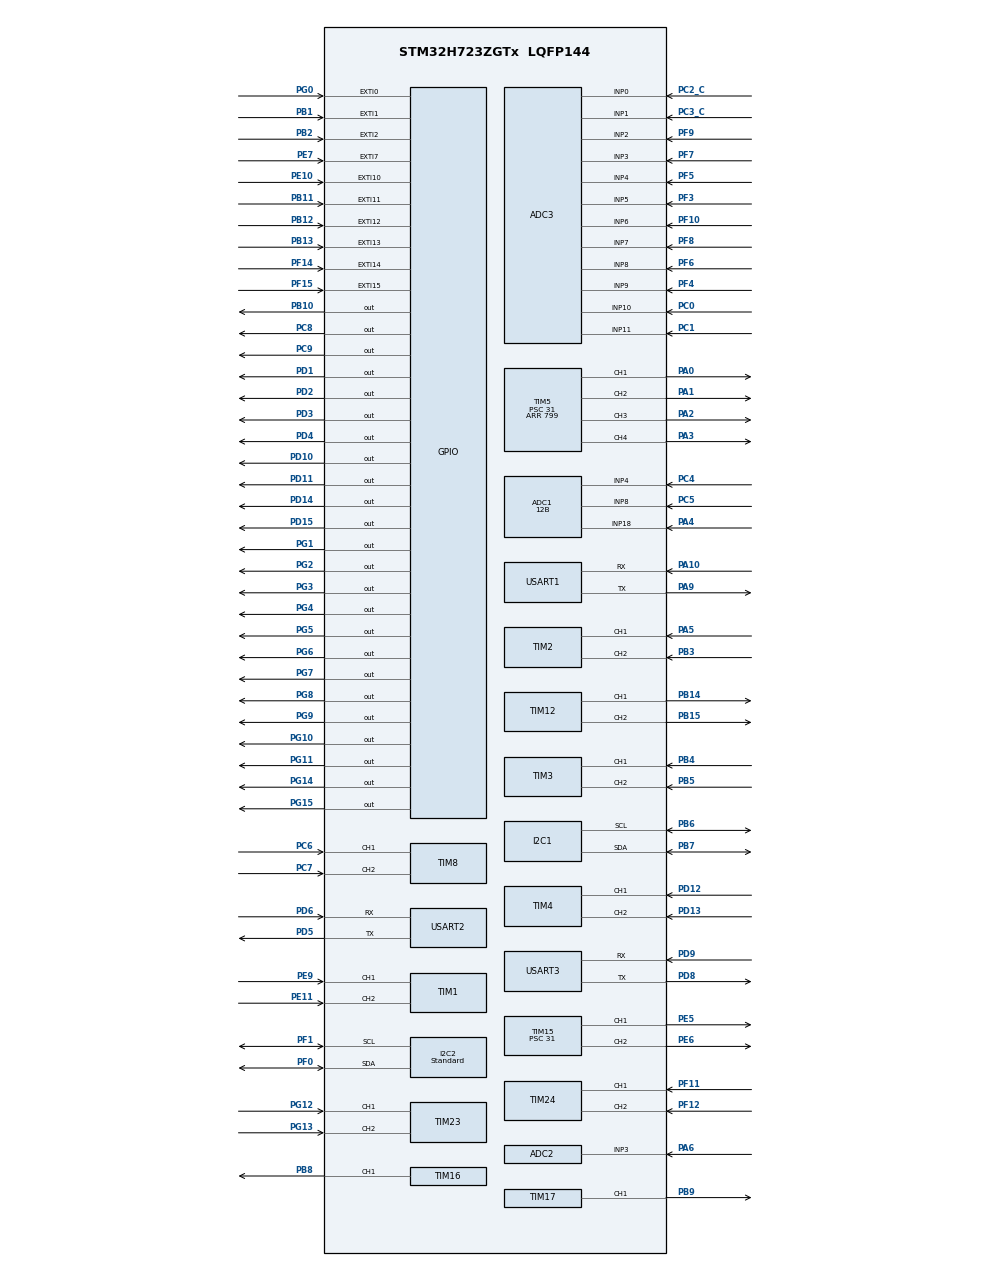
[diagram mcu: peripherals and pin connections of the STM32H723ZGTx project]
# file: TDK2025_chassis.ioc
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ADC1.Channel-0\#ChannelRegularConversion=ADC_CHANNEL_4
ADC1.Channel-1\#ChannelRegularConversion=ADC_CHANNEL_8
ADC1.Channel-2\#ChannelRegularConversion=ADC_CHANNEL_18
ADC1.ClockPrescaler=ADC_CLOCK_ASYNC_DIV256
ADC1.ClockPrescalerADC3=ADC_CLOCK_ASYNC_DIV64
ADC1.ContinuousConvMode=ENABLE
ADC1.ConversionDataManagement=ADC_CONVERSIONDATA_DR
ADC1.EOCSelection=ADC_EOC_SINGLE_CONV
ADC1.EnableInjectedConversion=DISABLE
ADC1.ExternalTrigConv=ADC_SOFTWARE_START
ADC1.NbrOfConversion=3
ADC1.NbrOfConversionFlag=1
ADC1.OffsetNumber-0\#ChannelRegularConversion=ADC_OFFSET_NONE
ADC1.OffsetNumber-1\#ChannelRegularConversion=ADC_OFFSET_NONE
ADC1.OffsetNumber-2\#ChannelRegularConversion=ADC_OFFSET_NONE
ADC1.OffsetSignedSaturation-0\#ChannelRegularConversion=DISABLE
ADC1.OffsetSignedSaturation-1\#ChannelRegularConversion=DISABLE
ADC1.OffsetSignedSaturation-2\#ChannelRegularConversion=DISABLE
ADC1.OversamplingMode=ENABLE
ADC1.Rank-0\#ChannelRegularConversion=1
ADC1.Rank-1\#ChannelRegularConversion=2
ADC1.Rank-2\#ChannelRegularConversion=3
ADC1.Ratio=2
ADC1.Resolution=ADC_RESOLUTION_12B
ADC1.SamplingTime-0\#ChannelRegularConversion=ADC_SAMPLETIME_2CYCLES_5
ADC1.SamplingTime-1\#ChannelRegularConversion=ADC_SAMPLETIME_2CYCLES_5
ADC1.SamplingTime-2\#ChannelRegularConversion=ADC_SAMPLETIME_2CYCLES_5
ADC1.master=1
ADC2.Channel-2\#ChannelRegularConversion=ADC_CHANNEL_3
ADC2.ClockPrescaler=ADC_CLOCK_ASYNC_DIV256
ADC2.ClockPrescalerADC3=ADC_CLOCK_ASYNC_DIV64
ADC2.NbrOfConversionFlag=1
ADC2.OffsetNumber-2\#ChannelRegularConversion=ADC_OFFSET_NONE
ADC2.OffsetSignedSaturation-2\#ChannelRegularConversion=DISABLE
ADC2.OversamplingMode=ENABLE
ADC2.Rank-2\#ChannelRegularConversion=1
ADC2.SamplingTime-2\#ChannelRegularConversion=ADC_SAMPLETIME_1CYCLE_5
ADC3.Channel-0\#ChannelRegularConversion=ADC_CHANNEL_0
ADC3.Channel-1\#ChannelRegularConversion=ADC_CHANNEL_1
ADC3.Channel-10\#ChannelRegularConversion=ADC_CHANNEL_10
ADC3.Channel-11\#ChannelRegularConversion=ADC_CHANNEL_11
ADC3.Channel-2\#ChannelRegularConversion=ADC_CHANNEL_2
ADC3.Channel-3\#ChannelRegularConversion=ADC_CHANNEL_3
ADC3.Channel-4\#ChannelRegularConversion=ADC_CHANNEL_4
ADC3.Channel-5\#ChannelRegularConversion=ADC_CHANNEL_5
ADC3.Channel-6\#ChannelRegularConversion=ADC_CHANNEL_6
ADC3.Channel-7\#ChannelRegularConversion=ADC_CHANNEL_7
ADC3.Channel-8\#ChannelRegularConversion=ADC_CHANNEL_8
ADC3.Channel-9\#ChannelRegularConversion=ADC_CHANNEL_9
ADC3.ClockPrescaler=ADC_CLOCK_ASYNC_DIV256
ADC3.ClockPrescalerADC3=ADC_CLOCK_ASYNC_DIV64
ADC3.ContinuousConvMode=ENABLE
ADC3.ConversionDataManagement=ADC_CONVERSIONDATA_DMA_CIRCULAR
ADC3.DMAContinuousRequests=ENABLE
ADC3.ExternalTrigConv=ADC_SOFTWARE_START
ADC3.NbrOfConversion=12
ADC3.NbrOfConversionFlag=1
ADC3.OffsetNumber-0\#ChannelRegularConversion=ADC_OFFSET_NONE
ADC3.OffsetNumber-1\#ChannelRegularConversion=ADC_OFFSET_NONE
ADC3.OffsetNumber-10\#ChannelRegularConversion=ADC_OFFSET_NONE
ADC3.OffsetNumber-11\#ChannelRegularConversion=ADC_OFFSET_NONE
ADC3.OffsetNumber-2\#ChannelRegularConversion=ADC_OFFSET_NONE
ADC3.OffsetNumber-3\#ChannelRegularConversion=ADC_OFFSET_NONE
ADC3.OffsetNumber-4\#ChannelRegularConversion=ADC_OFFSET_NONE
ADC3.OffsetNumber-5\#ChannelRegularConversion=ADC_OFFSET_NONE
ADC3.OffsetNumber-6\#ChannelRegularConversion=ADC_OFFSET_NONE
ADC3.OffsetNumber-7\#ChannelRegularConversion=ADC_OFFSET_NONE
ADC3.OffsetNumber-8\#ChannelRegularConversion=ADC_OFFSET_NONE
ADC3.OffsetNumber-9\#ChannelRegularConversion=ADC_OFFSET_NONE
ADC3.OffsetSign-0\#ChannelRegularConversion=ADC3_OFFSET_SIGN_NEGATIVE
ADC3.OffsetSign-1\#ChannelRegularConversion=ADC3_OFFSET_SIGN_NEGATIVE
ADC3.OffsetSign-10\#ChannelRegularConversion=ADC3_OFFSET_SIGN_NEGATIVE
ADC3.OffsetSign-11\#ChannelRegularConversion=ADC3_OFFSET_SIGN_NEGATIVE
ADC3.OffsetSign-2\#ChannelRegularConversion=ADC3_OFFSET_SIGN_NEGATIVE
ADC3.OffsetSign-3\#ChannelRegularConversion=ADC3_OFFSET_SIGN_NEGATIVE
ADC3.OffsetSign-4\#ChannelRegularConversion=ADC3_OFFSET_SIGN_NEGATIVE
ADC3.OffsetSign-5\#ChannelRegularConversion=ADC3_OFFSET_SIGN_NEGATIVE
ADC3.OffsetSign-6\#ChannelRegularConversion=ADC3_OFFSET_SIGN_NEGATIVE
ADC3.OffsetSign-7\#ChannelRegularConversion=ADC3_OFFSET_SIGN_NEGATIVE
ADC3.OffsetSign-8\#ChannelRegularConversion=ADC3_OFFSET_SIGN_NEGATIVE
ADC3.OffsetSign-9\#ChannelRegularConversion=ADC3_OFFSET_SIGN_NEGATIVE
ADC3.Rank-0\#ChannelRegularConversion=1
ADC3.Rank-1\#ChannelRegularConversion=2
ADC3.Rank-10\#ChannelRegularConversion=11
ADC3.Rank-11\#ChannelRegularConversion=12
ADC3.Rank-2\#ChannelRegularConversion=3
ADC3.Rank-3\#ChannelRegularConversion=4
ADC3.Rank-4\#ChannelRegularConversion=5
ADC3.Rank-5\#ChannelRegularConversion=6
ADC3.Rank-6\#ChannelRegularConversion=7
ADC3.Rank-7\#ChannelRegularConversion=8
ADC3.Rank-8\#ChannelRegularConversion=9
ADC3.Rank-9\#ChannelRegularConversion=10
ADC3.SamplingTime-0\#ChannelRegularConversion=ADC3_SAMPLETIME_2CYCLES_5
ADC3.SamplingTime-1\#ChannelRegularConversion=ADC3_SAMPLETIME_2CYCLES_5
ADC3.SamplingTime-10\#ChannelRegularConversion=ADC3_SAMPLETIME_2CYCLES_5
ADC3.SamplingTime-11\#ChannelRegularConversion=ADC3_SAMPLETIME_2CYCLES_5
ADC3.SamplingTime-2\#ChannelRegularConversion=ADC3_SAMPLETIME_2CYCLES_5
ADC3.SamplingTime-3\#ChannelRegularConversion=ADC3_SAMPLETIME_2CYCLES_5
ADC3.SamplingTime-4\#ChannelRegularConversion=ADC3_SAMPLETIME_2CYCLES_5
ADC3.SamplingTime-5\#ChannelRegularConversion=ADC3_SAMPLETIME_2CYCLES_5
ADC3.SamplingTime-6\#ChannelRegularConversion=ADC3_SAMPLETIME_2CYCLES_5
ADC3.SamplingTime-7\#ChannelRegularConversion=ADC3_SAMPLETIME_2CYCLES_5
ADC3.SamplingTime-8\#ChannelRegularConversion=ADC3_SAMPLETIME_2CYCLES_5
ADC3.SamplingTime-9\#ChannelRegularConversion=ADC3_SAMPLETIME_2CYCLES_5
Dma.ADC1.3.Direction=DMA_PERIPH_TO_MEMORY
Dma.ADC1.3.EventEnable=DISABLE
Dma.ADC1.3.FIFOMode=DMA_FIFOMODE_DISABLE
Dma.ADC1.3.Instance=DMA1_Stream0
Dma.ADC1.3.MemDataAlignment=DMA_MDATAALIGN_HALFWORD
Dma.ADC1.3.MemInc=DMA_MINC_ENABLE
Dma.ADC1.3.Mode=DMA_CIRCULAR
Dma.ADC1.3.PeriphDataAlignment=DMA_PDATAALIGN_HALFWORD
Dma.ADC1.3.PeriphInc=DMA_PINC_DISABLE
Dma.ADC1.3.Polarity=HAL_DMAMUX_REQ_GEN_RISING
Dma.ADC1.3.Priority=DMA_PRIORITY_LOW
Dma.ADC1.3.RequestNumber=1
Dma.ADC1.3.SignalID=NONE
Dma.ADC1.3.SyncEnable=DISABLE
Dma.ADC1.3.SyncPolarity=HAL_DMAMUX_SYNC_NO_EVENT
Dma.ADC1.3.SyncRequestNumber=1
Dma.ADC1.3.SyncSignalID=NONE
Dma.ADC3.2.Direction=DMA_PERIPH_TO_MEMORY
Dma.ADC3.2.EventEnable=DISABLE
Dma.ADC3.2.FIFOMode=DMA_FIFOMODE_DISABLE
Dma.ADC3.2.Instance=DMA1_Stream5
Dma.ADC3.2.MemDataAlignment=DMA_MDATAALIGN_HALFWORD
Dma.ADC3.2.MemInc=DMA_MINC_ENABLE
Dma.ADC3.2.Mode=DMA_CIRCULAR
Dma.ADC3.2.PeriphDataAlignment=DMA_PDATAALIGN_HALFWORD
Dma.ADC3.2.PeriphInc=DMA_PINC_DISABLE
Dma.ADC3.2.Polarity=HAL_DMAMUX_REQ_GEN_RISING
Dma.ADC3.2.Priority=DMA_PRIORITY_LOW
Dma.ADC3.2.RequestNumber=1
Dma.ADC3.2.SignalID=NONE
Dma.ADC3.2.SyncEnable=DISABLE
Dma.ADC3.2.SyncPolarity=HAL_DMAMUX_SYNC_NO_EVENT
Dma.ADC3.2.SyncRequestNumber=1
Dma.ADC3.2.SyncSignalID=NONE
Dma.I2C1_RX.4.Direction=DMA_PERIPH_TO_MEMORY
Dma.I2C1_RX.4.EventEnable=DISABLE
Dma.I2C1_RX.4.FIFOMode=DMA_FIFOMODE_DISABLE
Dma.I2C1_RX.4.Instance=DMA1_Stream6
Dma.I2C1_RX.4.MemDataAlignment=DMA_MDATAALIGN_BYTE
Dma.I2C1_RX.4.MemInc=DMA_MINC_ENABLE
Dma.I2C1_RX.4.Mode=DMA_NORMAL
Dma.I2C1_RX.4.PeriphDataAlignment=DMA_PDATAALIGN_BYTE
Dma.I2C1_RX.4.PeriphInc=DMA_PINC_DISABLE
Dma.I2C1_RX.4.Polarity=HAL_DMAMUX_REQ_GEN_RISING
Dma.I2C1_RX.4.Priority=DMA_PRIORITY_LOW
Dma.I2C1_RX.4.RequestNumber=1
Dma.I2C1_RX.4.SignalID=NONE
Dma.I2C1_RX.4.SyncEnable=DISABLE
Dma.I2C1_RX.4.SyncPolarity=HAL_DMAMUX_SYNC_NO_EVENT
Dma.I2C1_RX.4.SyncRequestNumber=1
Dma.I2C1_RX.4.SyncSignalID=NONE
Dma.I2C2_RX.5.Direction=DMA_PERIPH_TO_MEMORY
Dma.I2C2_RX.5.EventEnable=DISABLE
Dma.I2C2_RX.5.FIFOMode=DMA_FIFOMODE_DISABLE
Dma.I2C2_RX.5.Instance=DMA1_Stream2
Dma.I2C2_RX.5.MemDataAlignment=DMA_MDATAALIGN_BYTE
Dma.I2C2_RX.5.MemInc=DMA_MINC_ENABLE
Dma.I2C2_RX.5.Mode=DMA_NORMAL
Dma.I2C2_RX.5.PeriphDataAlignment=DMA_PDATAALIGN_BYTE
Dma.I2C2_RX.5.PeriphInc=DMA_PINC_DISABLE
Dma.I2C2_RX.5.Polarity=HAL_DMAMUX_REQ_GEN_RISING
Dma.I2C2_RX.5.Priority=DMA_PRIORITY_HIGH
Dma.I2C2_RX.5.RequestNumber=1
Dma.I2C2_RX.5.SignalID=NONE
Dma.I2C2_RX.5.SyncEnable=DISABLE
Dma.I2C2_RX.5.SyncPolarity=HAL_DMAMUX_SYNC_NO_EVENT
Dma.I2C2_RX.5.SyncRequestNumber=1
Dma.I2C2_RX.5.SyncSignalID=NONE
Dma.I2C2_TX.6.Direction=DMA_MEMORY_TO_PERIPH
Dma.I2C2_TX.6.EventEnable=DISABLE
Dma.I2C2_TX.6.FIFOMode=DMA_FIFOMODE_DISABLE
Dma.I2C2_TX.6.Instance=DMA1_Stream3
Dma.I2C2_TX.6.MemDataAlignment=DMA_MDATAALIGN_BYTE
Dma.I2C2_TX.6.MemInc=DMA_MINC_ENABLE
Dma.I2C2_TX.6.Mode=DMA_NORMAL
Dma.I2C2_TX.6.PeriphDataAlignment=DMA_PDATAALIGN_BYTE
Dma.I2C2_TX.6.PeriphInc=DMA_PINC_DISABLE
Dma.I2C2_TX.6.Polarity=HAL_DMAMUX_REQ_GEN_RISING
Dma.I2C2_TX.6.Priority=DMA_PRIORITY_MEDIUM
Dma.I2C2_TX.6.RequestNumber=1
Dma.I2C2_TX.6.SignalID=NONE
Dma.I2C2_TX.6.SyncEnable=DISABLE
Dma.I2C2_TX.6.SyncPolarity=HAL_DMAMUX_SYNC_NO_EVENT
Dma.I2C2_TX.6.SyncRequestNumber=1
Dma.I2C2_TX.6.SyncSignalID=NONE
Dma.Request0=USART1_TX
Dma.Request1=USART1_RX
Dma.Request2=ADC3
Dma.Request3=ADC1
Dma.Request4=I2C1_RX
Dma.Request5=I2C2_RX
Dma.Request6=I2C2_TX
Dma.Request7=USART3_RX
Dma.Request8=USART3_TX
Dma.USART1_RX.1.Direction=DMA_PERIPH_TO_MEMORY
Dma.USART1_RX.1.EventEnable=DISABLE
Dma.USART1_RX.1.FIFOMode=DMA_FIFOMODE_DISABLE
Dma.USART1_RX.1.Instance=DMA1_Stream1
Dma.USART1_RX.1.MemDataAlignment=DMA_MDATAALIGN_BYTE
Dma.USART1_RX.1.MemInc=DMA_MINC_ENABLE
Dma.USART1_RX.1.Mode=DMA_CIRCULAR
Dma.USART1_RX.1.PeriphDataAlignment=DMA_PDATAALIGN_BYTE
Dma.USART1_RX.1.PeriphInc=DMA_PINC_DISABLE
Dma.USART1_RX.1.Polarity=HAL_DMAMUX_REQ_GEN_RISING
Dma.USART1_RX.1.Priority=DMA_PRIORITY_VERY_HIGH
Dma.USART1_RX.1.RequestNumber=1
Dma.USART1_RX.1.SignalID=NONE
Dma.USART1_RX.1.SyncEnable=DISABLE
Dma.USART1_RX.1.SyncPolarity=HAL_DMAMUX_SYNC_NO_EVENT
Dma.USART1_RX.1.SyncRequestNumber=1
Dma.USART1_RX.1.SyncSignalID=NONE
Dma.USART1_TX.0.Direction=DMA_MEMORY_TO_PERIPH
Dma.USART1_TX.0.EventEnable=DISABLE
Dma.USART1_TX.0.FIFOMode=DMA_FIFOMODE_DISABLE
Dma.USART1_TX.0.Instance=DMA1_Stream4
Dma.USART1_TX.0.MemDataAlignment=DMA_MDATAALIGN_BYTE
Dma.USART1_TX.0.MemInc=DMA_MINC_ENABLE
Dma.USART1_TX.0.Mode=DMA_NORMAL
Dma.USART1_TX.0.PeriphDataAlignment=DMA_PDATAALIGN_BYTE
Dma.USART1_TX.0.PeriphInc=DMA_PINC_DISABLE
Dma.USART1_TX.0.Polarity=HAL_DMAMUX_REQ_GEN_RISING
Dma.USART1_TX.0.Priority=DMA_PRIORITY_VERY_HIGH
Dma.USART1_TX.0.RequestNumber=1
Dma.USART1_TX.0.SignalID=NONE
Dma.USART1_TX.0.SyncEnable=DISABLE
Dma.USART1_TX.0.SyncPolarity=HAL_DMAMUX_SYNC_NO_EVENT
Dma.USART1_TX.0.SyncRequestNumber=1
Dma.USART1_TX.0.SyncSignalID=NONE
Dma.USART3_RX.7.Direction=DMA_PERIPH_TO_MEMORY
Dma.USART3_RX.7.EventEnable=DISABLE
Dma.USART3_RX.7.FIFOMode=DMA_FIFOMODE_DISABLE
Dma.USART3_RX.7.Instance=DMA1_Stream7
Dma.USART3_RX.7.MemDataAlignment=DMA_MDATAALIGN_BYTE
Dma.USART3_RX.7.MemInc=DMA_MINC_ENABLE
Dma.USART3_RX.7.Mode=DMA_CIRCULAR
Dma.USART3_RX.7.PeriphDataAlignment=DMA_PDATAALIGN_BYTE
Dma.USART3_RX.7.PeriphInc=DMA_PINC_DISABLE
Dma.USART3_RX.7.Polarity=HAL_DMAMUX_REQ_GEN_RISING
Dma.USART3_RX.7.Priority=DMA_PRIORITY_VERY_HIGH
Dma.USART3_RX.7.RequestNumber=1
Dma.USART3_RX.7.SignalID=NONE
Dma.USART3_RX.7.SyncEnable=DISABLE
Dma.USART3_RX.7.SyncPolarity=HAL_DMAMUX_SYNC_NO_EVENT
Dma.USART3_RX.7.SyncRequestNumber=1
Dma.USART3_RX.7.SyncSignalID=NONE
Dma.USART3_TX.8.Direction=DMA_MEMORY_TO_PERIPH
Dma.USART3_TX.8.EventEnable=DISABLE
Dma.USART3_TX.8.FIFOMode=DMA_FIFOMODE_DISABLE
Dma.USART3_TX.8.Instance=DMA2_Stream0
Dma.USART3_TX.8.MemDataAlignment=DMA_MDATAALIGN_BYTE
Dma.USART3_TX.8.MemInc=DMA_MINC_ENABLE
Dma.USART3_TX.8.Mode=DMA_NORMAL
Dma.USART3_TX.8.PeriphDataAlignment=DMA_PDATAALIGN_BYTE
Dma.USART3_TX.8.PeriphInc=DMA_PINC_DISABLE
Dma.USART3_TX.8.Polarity=HAL_DMAMUX_REQ_GEN_RISING
Dma.USART3_TX.8.Priority=DMA_PRIORITY_VERY_HIGH
Dma.USART3_TX.8.RequestNumber=1
Dma.USART3_TX.8.SignalID=NONE
Dma.USART3_TX.8.SyncEnable=DISABLE
Dma.USART3_TX.8.SyncPolarity=HAL_DMAMUX_SYNC_NO_EVENT
Dma.USART3_TX.8.SyncRequestNumber=1
Dma.USART3_TX.8.SyncSignalID=NONE
I2C1.Timing=0x20A0C4DF
I2C2.I2C_Fall_Time=0
I2C2.I2C_Rise_Time=0
I2C2.I2C_Speed_Mode=I2C_Standard
I2C2.Timing=0x20A0C4DF
Mcu.Family=STM32H7
Mcu.Name=STM32H723ZGTx
Mcu.Package=LQFP144
NVIC.ADC3_IRQn=true\:1\:0\:true\:false\:true\:true\:true\:true
NVIC.ADC_IRQn=true\:0\:0\:false\:false\:true\:true\:true\:true
NVIC.DMA1_Stream0_IRQn=true\:0\:0\:true\:false\:true\:false\:true\:true
NVIC.DMA1_Stream1_IRQn=true\:0\:0\:false\:false\:true\:false\:true\:true
NVIC.DMA1_Stream2_IRQn=true\:0\:0\:false\:false\:true\:false\:true\:true
NVIC.DMA1_Stream3_IRQn=true\:0\:0\:false\:false\:true\:false\:true\:true
NVIC.DMA1_Stream4_IRQn=true\:0\:0\:false\:false\:true\:false\:true\:true
NVIC.DMA1_Stream5_IRQn=true\:0\:0\:false\:false\:true\:false\:true\:true
NVIC.DMA1_Stream6_IRQn=true\:0\:0\:false\:false\:true\:false\:true\:true
NVIC.DMA1_Stream7_IRQn=true\:0\:0\:false\:false\:true\:false\:true\:true
NVIC.DMA2_Stream0_IRQn=true\:0\:0\:false\:false\:true\:false\:true\:true
NVIC.EXTI0_IRQn=true\:0\:0\:false\:false\:true\:true\:true\:true
NVIC.EXTI15_10_IRQn=true\:0\:0\:false\:false\:true\:true\:true\:true
NVIC.EXTI1_IRQn=true\:0\:0\:false\:false\:true\:true\:true\:true
NVIC.EXTI2_IRQn=true\:0\:0\:false\:false\:true\:true\:true\:true
NVIC.EXTI9_5_IRQn=true\:0\:0\:false\:false\:true\:true\:true\:true
NVIC.I2C2_ER_IRQn=true\:0\:0\:false\:false\:true\:true\:true\:true
NVIC.I2C2_EV_IRQn=true\:0\:0\:false\:false\:true\:true\:true\:true
NVIC.PriorityGroup=NVIC_PRIORITYGROUP_4
NVIC.RCC_IRQn=true\:0\:0\:false\:false\:true\:true\:false\:true
NVIC.TIM6_DAC_IRQn=true\:0\:0\:false\:false\:true\:true\:true\:true
NVIC.TIM7_IRQn=true\:0\:0\:false\:false\:true\:true\:true\:true
NVIC.TIM8_TRG_COM_TIM14_IRQn=true\:0\:0\:false\:false\:true\:true\:true\:true
NVIC.TIM8_UP_TIM13_IRQn=true\:0\:0\:false\:false\:true\:true\:true\:true
NVIC.USART1_IRQn=true\:0\:0\:false\:false\:true\:true\:true\:true
NVIC.USART3_IRQn=true\:0\:0\:false\:false\:true\:true\:true\:true
PA0.GPIO_PuPd=GPIO_PULLDOWN
PA0.Signal=S_TIM5_CH1
PA1.GPIO_PuPd=GPIO_PULLDOWN
PA1.Signal=S_TIM5_CH2
PA10.Mode=Asynchronous
PA10.Signal=USART1_RX
PA13(JTMS/SWDIO).Signal=DEBUG_JTMS-SWDIO
PA14(JTCK/SWCLK).Signal=DEBUG_JTCK-SWCLK
PA2.GPIO_PuPd=GPIO_PULLDOWN
PA2.Signal=S_TIM5_CH3
PA3.GPIO_PuPd=GPIO_PULLDOWN
PA3.Signal=S_TIM5_CH4
PA4.Signal=ADCx_INP18
PA5.Signal=S_TIM2_CH1_ETR
PA6.Signal=ADCx_INP3
PA9.Mode=Asynchronous
PA9.Signal=USART1_TX
PB1.Signal=GPXTI1
PB10.PinState=GPIO_PIN_RESET
PB10.Signal=GPIO_Output
PB11.Signal=GPXTI11
PB12.Signal=GPXTI12
PB13.Signal=GPXTI13
PB14.Signal=S_TIM12_CH1
PB15.Signal=S_TIM12_CH2
PB2.GPIO_ModeDefaultEXTI=GPIO_MODE_IT_FALLING
PB2.GPIO_PuPd=GPIO_PULLUP
PB2.Signal=GPXTI2
PB3(JTDO/TRACESWO).Signal=S_TIM2_CH2
PB4(NJTRST).Signal=S_TIM3_CH1
PB5.Signal=S_TIM3_CH2
PB6.GPIO_Pu=GPIO_PULLUP
PB6.Mode=I2C
PB6.Signal=I2C1_SCL
PB7.GPIO_Pu=GPIO_PULLUP
PB7.Mode=I2C
PB7.Signal=I2C1_SDA
PB8.Signal=S_TIM16_CH1
PB9.Signal=S_TIM17_CH1
PC0.Signal=ADCx_INP10
PC1.Signal=ADCx_INP11
PC14-OSC32_IN.Mode=LSE-External-Oscillator
PC14-OSC32_IN.Signal=RCC_OSC32_IN
PC15-OSC32_OUT.Mode=LSE-External-Oscillator
PC15-OSC32_OUT.Signal=RCC_OSC32_OUT
PC2_C.Mode=IN0-Single-Ended
PC2_C.Signal=ADC3_INP0
PC3_C.Mode=IN1-Single-Ended
PC3_C.Signal=ADC3_INP1
PC4.Signal=ADCx_INP4
PC5.Signal=ADCx_INP8
PC6.Signal=S_TIM8_CH1
PC7.Signal=S_TIM8_CH2
PC8.Signal=GPIO_Output
PC9.Signal=GPIO_Output
PD1.Signal=GPIO_Output
PD10.Signal=GPIO_Output
PD11.Signal=GPIO_Output
PD12.Signal=S_TIM4_CH1
PD13.Signal=S_TIM4_CH2
PD14.Signal=GPIO_Output
PD15.Signal=GPIO_Output
PD2.Signal=GPIO_Output
PD3.Signal=GPIO_Output
PD4.Signal=GPIO_Output
PD5.Mode=Asynchronous
PD5.Signal=USART2_TX
PD6.Mode=Asynchronous
PD6.Signal=USART2_RX
PD8.Mode=Asynchronous
PD8.Signal=USART3_TX
PD9.Mode=Asynchronous
PD9.Signal=USART3_RX
PE10.Signal=GPXTI10
PE11.Signal=S_TIM1_CH2
PE5.Signal=S_TIM15_CH1
PE6.Signal=S_TIM15_CH2
PE7.Signal=GPXTI7
PE9.Signal=S_TIM1_CH1
PF0.GPIO_Pu=GPIO_PULLUP
PF0.Mode=I2C
PF0.Signal=I2C2_SDA
PF1.GPIO_Pu=GPIO_PULLUP
PF1.Mode=I2C
PF1.Signal=I2C2_SCL
PF10.Mode=IN6-Single-Ended
PF10.Signal=ADC3_INP6
PF11.Mode=Encoder_Interface
PF11.Signal=TIM24_CH1
PF12.Signal=S_TIM24_CH2
PF14.Signal=GPXTI14
PF15.Signal=GPXTI15
PF3.Mode=IN5-Single-Ended
PF3.Signal=ADC3_INP5
PF4.Mode=IN9-Single-Ended
PF4.Signal=ADC3_INP9
PF5.Mode=IN4-Single-Ended
PF5.Signal=ADC3_INP4
PF6.Mode=IN8-Single-Ended
PF6.Signal=ADC3_INP8
PF7.Mode=IN3-Single-Ended
PF7.Signal=ADC3_INP3
PF8.Mode=IN7-Single-Ended
PF8.Signal=ADC3_INP7
PF9.Mode=IN2-Single-Ended
PF9.Signal=ADC3_INP2
PG0.Signal=GPXTI0
PG1.Signal=GPIO_Output
PG10.Signal=GPIO_Output
PG11.Signal=GPIO_Output
PG12.Mode=Encoder_Interface
PG12.Signal=TIM23_CH1
PG13.Signal=S_TIM23_CH2
PG14.Signal=GPIO_Output
PG15.Signal=GPIO_Output
PG2.Signal=GPIO_Output
PG3.Signal=GPIO_Output
PG4.Signal=GPIO_Output
PG5.Signal=GPIO_Output
PG6.Signal=GPIO_Output
PG7.Signal=GPIO_Output
PG8.Signal=GPIO_Output
PG9.Signal=GPIO_Output
PH0-OSC_IN.Mode=HSE-External-Oscillator
PH0-OSC_IN.Signal=RCC_OSC_IN
PH1-OSC_OUT.Mode=HSE-External-Oscillator
PH1-OSC_OUT.Signal=RCC_OSC_OUT
ProjectManager.HeapSize=0x200
ProjectManager.StackSize=0x400
ProjectManager.TargetToolchain=STM32CubeIDE
RCC.ADCFreq_Value=129000000
RCC.APB1Freq_Value=128000000
RCC.APB2Freq_Value=128000000
RCC.APB3Freq_Value=128000000
RCC.APB4Freq_Value=128000000
RCC.CortexFreq_Value=512000000
RCC.D1PPRE=RCC_APB3_DIV2
RCC.D2PPRE1=RCC_APB1_DIV2
RCC.D2PPRE2=RCC_APB2_DIV2
RCC.D3PPRE=RCC_APB4_DIV2
RCC.DIVM1=4
RCC.DIVN1=32
RCC.DIVP1=1
RCC.HCLKFreq_Value=256000000
RCC.HPRE=RCC_HCLK_DIV2
RCC.HSE_VALUE=8000000
RCC.PLL2FRACN=0
RCC.PLL3FRACN=0
RCC.PLLFRACN=0
RCC.SYSCLKFreq_VALUE=512000000
RCC.SYSCLKSource=RCC_SYSCLKSOURCE_PLLCLK
RCC.USBFreq_Value=256000000
SH.ADCx_INP10.0=ADC3_INP10,IN10-Single-Ended
SH.ADCx_INP11.0=ADC3_INP11,IN11-Single-Ended
SH.ADCx_INP18.0=ADC1_INP18,IN18-Single-Ended
SH.ADCx_INP3.0=ADC2_INP3,IN3-Single-Ended
SH.ADCx_INP4.0=ADC1_INP4,IN4-Single-Ended
SH.ADCx_INP8.0=ADC1_INP8,IN8-Single-Ended
SH.S_TIM12_CH1.0=TIM12_CH1,PWM Generation1 CH1
SH.S_TIM12_CH2.0=TIM12_CH2,PWM Generation2 CH2
SH.S_TIM15_CH1.0=TIM15_CH1,PWM Generation1 CH1
SH.S_TIM15_CH2.0=TIM15_CH2,PWM Generation2 CH2
SH.S_TIM16_CH1.0=TIM16_CH1,PWM Generation1 CH1
SH.S_TIM17_CH1.0=TIM17_CH1,PWM Generation1 CH1
SH.S_TIM1_CH1.0=TIM1_CH1,Encoder_Interface
SH.S_TIM1_CH2.0=TIM1_CH2,Encoder_Interface
SH.S_TIM23_CH2.0=TIM23_CH2,Encoder_Interface
SH.S_TIM24_CH2.0=TIM24_CH2,Encoder_Interface
SH.S_TIM2_CH1_ETR.0=TIM2_CH1,Encoder_Interface
SH.S_TIM2_CH2.0=TIM2_CH2,Encoder_Interface
SH.S_TIM3_CH1.0=TIM3_CH1,Encoder_Interface
SH.S_TIM3_CH2.0=TIM3_CH2,Encoder_Interface
SH.S_TIM4_CH1.0=TIM4_CH1,Encoder_Interface
SH.S_TIM4_CH2.0=TIM4_CH2,Encoder_Interface
SH.S_TIM5_CH1.0=TIM5_CH1,PWM Generation1 CH1
SH.S_TIM5_CH2.0=TIM5_CH2,PWM Generation2 CH2
SH.S_TIM5_CH3.0=TIM5_CH3,PWM Generation3 CH3
SH.S_TIM5_CH4.0=TIM5_CH4,PWM Generation4 CH4
SH.S_TIM8_CH1.0=TIM8_CH1,Encoder_Interface
SH.S_TIM8_CH2.0=TIM8_CH2,Encoder_Interface
TIM1.EncoderMode=TIM_ENCODERMODE_TI12
TIM12.Channel-PWM\ Generation1\ CH1=TIM_CHANNEL_1
TIM12.Channel-PWM\ Generation2\ CH2=TIM_CHANNEL_2
TIM13.Period=9999
TIM13.Prescaler=255
TIM14.Period=999
TIM14.Prescaler=255
TIM15.Channel-PWM\ Generation1\ CH1=TIM_CHANNEL_1
TIM15.Channel-PWM\ Generation2\ CH2=TIM_CHANNEL_2
TIM15.Period=799
TIM15.Prescaler=31
TIM16.Channel=TIM_CHANNEL_1
TIM16.Period=799
TIM16.Prescaler=31
TIM17.Channel=TIM_CHANNEL_1
TIM17.Period=799
TIM17.Prescaler=31
TIM2.EncoderMode=TIM_ENCODERMODE_TI12
TIM23.EncoderMode=TIM_ENCODERMODE_TI12
TIM24.EncoderMode=TIM_ENCODERMODE_TI12
TIM3.EncoderMode=TIM_ENCODERMODE_TI12
TIM4.EncoderMode=TIM_ENCODERMODE_TI12
TIM5.Channel-PWM\ Generation1\ CH1=TIM_CHANNEL_1
TIM5.Channel-PWM\ Generation2\ CH2=TIM_CHANNEL_2
TIM5.Channel-PWM\ Generation3\ CH3=TIM_CHANNEL_3
TIM5.Channel-PWM\ Generation4\ CH4=TIM_CHANNEL_4
TIM5.Period=799
TIM5.Prescaler=31
TIM6.Period=999
TIM6.Prescaler=255
TIM7.Period=9999
TIM7.Prescaler=255
TIM8.EncoderMode=TIM_ENCODERMODE_TI12
USART1.VirtualMode-Asynchronous=VM_ASYNC
USART2.VirtualMode-Asynchronous=VM_ASYNC
USART3.VirtualMode-Asynchronous=VM_ASYNC
VP_MEMORYMAP_VS_MEMORYMAP.Mode=CurAppReg
VP_TIM13_VS_ClockSourceINT.Mode=Enable_Timer
VP_TIM14_VS_ClockSourceINT.Mode=Enable_Timer
VP_TIM16_VS_ClockSourceINT.Mode=Enable_Timer
VP_TIM17_VS_ClockSourceINT.Mode=Enable_Timer
VP_TIM6_VS_ClockSourceINT.Mode=Enable_Timer
VP_TIM7_VS_ClockSourceINT.Mode=Enable_Timer
board=custom

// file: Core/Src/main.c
/* USER CODE BEGIN Header */
/**
  ******************************************************************************
  * @file           : main.c
  * @brief          : Main program body
  ******************************************************************************
  * @attention
  *
  * Copyright (c) 2025 STMicroelectronics.
  * All rights reserved.
  *
  * This software is licensed under terms that can be found in the LICENSE file
  * in the root directory of this software component.
  * If no LICENSE file comes with this software, it is provided AS-IS.
  *
  ******************************************************************************
  */
/* USER CODE END Header */
#include "main.h"

/* USER CODE BEGIN Includes */
#include "mainpp.h"
/* USER CODE END Includes */

ADC_HandleTypeDef hadc1;
ADC_HandleTypeDef hadc2;
ADC_HandleTypeDef hadc3;
DMA_HandleTypeDef hdma_adc1;
DMA_HandleTypeDef hdma_adc3;

I2C_HandleTypeDef hi2c1;
I2C_HandleTypeDef hi2c2;
DMA_HandleTypeDef hdma_i2c1_rx;
DMA_HandleTypeDef hdma_i2c2_rx;
DMA_HandleTypeDef hdma_i2c2_tx;

TIM_HandleTypeDef htim1;
TIM_HandleTypeDef htim2;
TIM_HandleTypeDef htim3;
TIM_HandleTypeDef htim4;
TIM_HandleTypeDef htim5;
TIM_HandleTypeDef htim6;
TIM_HandleTypeDef htim7;
TIM_HandleTypeDef htim8;
TIM_HandleTypeDef htim12;
TIM_HandleTypeDef htim13;
TIM_HandleTypeDef htim14;
TIM_HandleTypeDef htim15;
TIM_HandleTypeDef htim16;
TIM_HandleTypeDef htim17;
TIM_HandleTypeDef htim23;
TIM_HandleTypeDef htim24;

UART_HandleTypeDef huart1;
UART_HandleTypeDef huart2;
UART_HandleTypeDef huart3;
DMA_HandleTypeDef hdma_usart1_tx;
DMA_HandleTypeDef hdma_usart1_rx;
DMA_HandleTypeDef hdma_usart3_rx;
DMA_HandleTypeDef hdma_usart3_tx;

void SystemClock_Config(void);
void PeriphCommonClock_Config(void);
static void MX_GPIO_Init(void);
static void MX_DMA_Init(void);
static void MX_USART1_UART_Init(void);
static void MX_TIM4_Init(void);
static void MX_TIM5_Init(void);
static void MX_TIM6_Init(void);
static void MX_TIM15_Init(void);
static void MX_TIM1_Init(void);
static void MX_TIM2_Init(void);
static void MX_I2C1_Init(void);
static void MX_ADC3_Init(void);
static void MX_TIM7_Init(void);
static void MX_I2C2_Init(void);
static void MX_TIM12_Init(void);
static void MX_TIM23_Init(void);
static void MX_TIM24_Init(void);
static void MX_TIM8_Init(void);
static void MX_TIM13_Init(void);
static void MX_ADC1_Init(void);
static void MX_TIM3_Init(void);
static void MX_TIM16_Init(void);
static void MX_TIM17_Init(void);
static void MX_ADC2_Init(void);
static void MX_USART2_UART_Init(void);
static void MX_TIM14_Init(void);
static void MX_USART3_UART_Init(void);

int main(void)
{

  /* MCU Configuration--------------------------------------------------------*/

  /* Reset of all peripherals, Initializes the Flash interface and the Systick. */

	HAL_Init();

  /* Configure the system clock */
  SystemClock_Config();

  /* Configure the peripherals common clocks */
  PeriphCommonClock_Config();

  /* Initialize all configured peripherals */
  MX_GPIO_Init();
  MX_DMA_Init();
  MX_USART1_UART_Init();
  MX_TIM4_Init();
  MX_TIM5_Init();
  MX_TIM6_Init();
  MX_TIM15_Init();
  MX_TIM1_Init();
  MX_TIM2_Init();
  MX_I2C1_Init();
  MX_ADC3_Init();
  MX_TIM7_Init();
  MX_I2C2_Init();
  MX_TIM12_Init();
  MX_TIM23_Init();
  MX_TIM24_Init();
  MX_TIM8_Init();
  MX_TIM13_Init();
  MX_ADC1_Init();
  MX_TIM3_Init();
  MX_TIM16_Init();
  MX_TIM17_Init();
  MX_ADC2_Init();
  MX_USART2_UART_Init();
  MX_TIM14_Init();
  MX_USART3_UART_Init();
  /* USER CODE BEGIN 2 */
  //hadc1.Init.DMAContinuousRequests = ENABLE;
  main_function();
  /* USER CODE END 2 */

  /* Infinite loop */
  while (1)
  {

    /* USER CODE BEGIN 3 */
    // Chassis::update() 現在在 TIM6 中斷中執行
    // 主循環可以處理其他任務或休眠
   // HAL_Delay(100);  // 減少主循環的 CPU 佔用
  }
  /* USER CODE END 3 */
}

void SystemClock_Config(void)
{
  RCC_OscInitTypeDef RCC_OscInitStruct = {0};
  RCC_ClkInitTypeDef RCC_ClkInitStruct = {0};

  /** Supply configuration update enable
  */
  HAL_PWREx_ConfigSupply(PWR_LDO_SUPPLY);

  /** Configure the main internal regulator output voltage
  */
  __HAL_PWR_VOLTAGESCALING_CONFIG(PWR_REGULATOR_VOLTAGE_SCALE0);

  while(!__HAL_PWR_GET_FLAG(PWR_FLAG_VOSRDY)) {}

  /** Initializes the RCC Oscillators according to the specified parameters
  * in the RCC_OscInitTypeDef structure.
  */
  RCC_OscInitStruct.OscillatorType = RCC_OSCILLATORTYPE_HSI;
  RCC_OscInitStruct.HSIState = RCC_HSI_DIV1;
  RCC_OscInitStruct.HSICalibrationValue = 64;
  RCC_OscInitStruct.PLL.PLLState = RCC_PLL_ON;
  RCC_OscInitStruct.PLL.PLLSource = RCC_PLLSOURCE_HSI;
  RCC_OscInitStruct.PLL.PLLM = 4;
  RCC_OscInitStruct.PLL.PLLN = 32;
  RCC_OscInitStruct.PLL.PLLP = 1;
  RCC_OscInitStruct.PLL.PLLQ = 2;
  RCC_OscInitStruct.PLL.PLLR = 2;
  RCC_OscInitStruct.PLL.PLLRGE = RCC_PLL1VCIRANGE_3;
  RCC_OscInitStruct.PLL.PLLVCOSEL = RCC_PLL1VCOWIDE;
  RCC_OscInitStruct.PLL.PLLFRACN = 0;
  if (HAL_RCC_OscConfig(&RCC_OscInitStruct) != HAL_OK)
  {
    Error_Handler();
  }

  /** Initializes the CPU, AHB and APB buses clocks
  */
  RCC_ClkInitStruct.ClockType = RCC_CLOCKTYPE_HCLK|RCC_CLOCKTYPE_SYSCLK
                              |RCC_CLOCKTYPE_PCLK1|RCC_CLOCKTYPE_PCLK2
                              |RCC_CLOCKTYPE_D3PCLK1|RCC_CLOCKTYPE_D1PCLK1;
  RCC_ClkInitStruct.SYSCLKSource = RCC_SYSCLKSOURCE_PLLCLK;
  RCC_ClkInitStruct.SYSCLKDivider = RCC_SYSCLK_DIV1;
  RCC_ClkInitStruct.AHBCLKDivider = RCC_HCLK_DIV2;
  RCC_ClkInitStruct.APB3CLKDivider = RCC_APB3_DIV2;
  RCC_ClkInitStruct.APB1CLKDivider = RCC_APB1_DIV2;
  RCC_ClkInitStruct.APB2CLKDivider = RCC_APB2_DIV2;
  RCC_ClkInitStruct.APB4CLKDivider = RCC_APB4_DIV2;

  if (HAL_RCC_ClockConfig(&RCC_ClkInitStruct, FLASH_LATENCY_3) != HAL_OK)
  {
    Error_Handler();
  }
}

void PeriphCommonClock_Config(void)
{
  RCC_PeriphCLKInitTypeDef PeriphClkInitStruct = {0};

  /** Initializes the peripherals clock
  */
  PeriphClkInitStruct.PeriphClockSelection = RCC_PERIPHCLK_ADC;
  PeriphClkInitStruct.PLL2.PLL2M = 32;
  PeriphClkInitStruct.PLL2.PLL2N = 129;
  PeriphClkInitStruct.PLL2.PLL2P = 2;
  PeriphClkInitStruct.PLL2.PLL2Q = 2;
  PeriphClkInitStruct.PLL2.PLL2R = 2;
  PeriphClkInitStruct.PLL2.PLL2RGE = RCC_PLL2VCIRANGE_1;
  PeriphClkInitStruct.PLL2.PLL2VCOSEL = RCC_PLL2VCOWIDE;
  PeriphClkInitStruct.PLL2.PLL2FRACN = 0;
  PeriphClkInitStruct.AdcClockSelection = RCC_ADCCLKSOURCE_PLL2;
  if (HAL_RCCEx_PeriphCLKConfig(&PeriphClkInitStruct) != HAL_OK)
  {
    Error_Handler();
  }
}

static void MX_ADC1_Init(void)
{

  ADC_MultiModeTypeDef multimode = {0};
  ADC_ChannelConfTypeDef sConfig = {0};

  /** Common config
  */
  hadc1.Instance = ADC1;
  hadc1.Init.ClockPrescaler = ADC_CLOCK_ASYNC_DIV256;
  hadc1.Init.Resolution = ADC_RESOLUTION_12B;
  hadc1.Init.ScanConvMode = ADC_SCAN_ENABLE;
  hadc1.Init.EOCSelection = ADC_EOC_SINGLE_CONV;
  hadc1.Init.LowPowerAutoWait = DISABLE;
  hadc1.Init.ContinuousConvMode = ENABLE;
  hadc1.Init.NbrOfConversion = 3;
  hadc1.Init.DiscontinuousConvMode = DISABLE;
  hadc1.Init.ExternalTrigConv = ADC_SOFTWARE_START;
  hadc1.Init.ExternalTrigConvEdge = ADC_EXTERNALTRIGCONVEDGE_NONE;
  hadc1.Init.ConversionDataManagement = ADC_CONVERSIONDATA_DR;
  hadc1.Init.Overrun = ADC_OVR_DATA_PRESERVED;
  hadc1.Init.LeftBitShift = ADC_LEFTBITSHIFT_NONE;
  hadc1.Init.OversamplingMode = ENABLE;
  hadc1.Init.Oversampling.Ratio = 2;
  hadc1.Init.Oversampling.RightBitShift = ADC_RIGHTBITSHIFT_NONE;
  hadc1.Init.Oversampling.TriggeredMode = ADC_TRIGGEREDMODE_SINGLE_TRIGGER;
  hadc1.Init.Oversampling.OversamplingStopReset = ADC_REGOVERSAMPLING_CONTINUED_MODE;
  if (HAL_ADC_Init(&hadc1) != HAL_OK)
  {
    Error_Handler();
  }

  /** Configure the ADC multi-mode
  */
  multimode.Mode = ADC_MODE_INDEPENDENT;
  if (HAL_ADCEx_MultiModeConfigChannel(&hadc1, &multimode) != HAL_OK)
  {
    Error_Handler();
  }

  /** Configure Regular Channel
  */
  sConfig.Channel = ADC_CHANNEL_4;
  sConfig.Rank = ADC_REGULAR_RANK_1;
  sConfig.SamplingTime = ADC_SAMPLETIME_2CYCLES_5;
  sConfig.SingleDiff = ADC_SINGLE_ENDED;
  sConfig.OffsetNumber = ADC_OFFSET_NONE;
  sConfig.Offset = 0;
  sConfig.OffsetSignedSaturation = DISABLE;
  if (HAL_ADC_ConfigChannel(&hadc1, &sConfig) != HAL_OK)
  {
    Error_Handler();
  }

  /** Configure Regular Channel
  */
  sConfig.Channel = ADC_CHANNEL_8;
  sConfig.Rank = ADC_REGULAR_RANK_2;
  if (HAL_ADC_ConfigChannel(&hadc1, &sConfig) != HAL_OK)
  {
    Error_Handler();
  }

  /** Configure Regular Channel
  */
  sConfig.Channel = ADC_CHANNEL_18;
  sConfig.Rank = ADC_REGULAR_RANK_3;
  if (HAL_ADC_ConfigChannel(&hadc1, &sConfig) != HAL_OK)
  {
    Error_Handler();
  }

}

static void MX_ADC2_Init(void)
{

  ADC_ChannelConfTypeDef sConfig = {0};

  /** Common config
  */
  hadc2.Instance = ADC2;
  hadc2.Init.ClockPrescaler = ADC_CLOCK_ASYNC_DIV256;
  hadc2.Init.Resolution = ADC_RESOLUTION_16B;
  hadc2.Init.ScanConvMode = ADC_SCAN_DISABLE;
  hadc2.Init.EOCSelection = ADC_EOC_SINGLE_CONV;
  hadc2.Init.LowPowerAutoWait = DISABLE;
  hadc2.Init.ContinuousConvMode = DISABLE;
  hadc2.Init.NbrOfConversion = 1;
  hadc2.Init.DiscontinuousConvMode = DISABLE;
  hadc2.Init.ExternalTrigConv = ADC_SOFTWARE_START;
  hadc2.Init.ExternalTrigConvEdge = ADC_EXTERNALTRIGCONVEDGE_NONE;
  hadc2.Init.ConversionDataManagement = ADC_CONVERSIONDATA_DR;
  hadc2.Init.Overrun = ADC_OVR_DATA_PRESERVED;
  hadc2.Init.LeftBitShift = ADC_LEFTBITSHIFT_NONE;
  hadc2.Init.OversamplingMode = ENABLE;
  hadc2.Init.Oversampling.Ratio = 1;
  hadc2.Init.Oversampling.RightBitShift = ADC_RIGHTBITSHIFT_NONE;
  hadc2.Init.Oversampling.TriggeredMode = ADC_TRIGGEREDMODE_SINGLE_TRIGGER;
  hadc2.Init.Oversampling.OversamplingStopReset = ADC_REGOVERSAMPLING_CONTINUED_MODE;
  if (HAL_ADC_Init(&hadc2) != HAL_OK)
  {
    Error_Handler();
  }

  /** Configure Regular Channel
  */
  sConfig.Channel = ADC_CHANNEL_3;
  sConfig.Rank = ADC_REGULAR_RANK_1;
  sConfig.SamplingTime = ADC_SAMPLETIME_1CYCLE_5;
  sConfig.SingleDiff = ADC_SINGLE_ENDED;
  sConfig.OffsetNumber = ADC_OFFSET_NONE;
  sConfig.Offset = 0;
  sConfig.OffsetSignedSaturation = DISABLE;
  if (HAL_ADC_ConfigChannel(&hadc2, &sConfig) != HAL_OK)
  {
    Error_Handler();
  }

}

static void MX_ADC3_Init(void)
{

  ADC_ChannelConfTypeDef sConfig = {0};

  /** Common config
  */
  hadc3.Instance = ADC3;
  hadc3.Init.ClockPrescaler = ADC_CLOCK_ASYNC_DIV64;
  hadc3.Init.Resolution = ADC_RESOLUTION_12B;
  hadc3.Init.DataAlign = ADC3_DATAALIGN_RIGHT;
  hadc3.Init.ScanConvMode = ADC_SCAN_ENABLE;
  hadc3.Init.EOCSelection = ADC_EOC_SINGLE_CONV;
  hadc3.Init.LowPowerAutoWait = DISABLE;
  hadc3.Init.ContinuousConvMode = ENABLE;
  hadc3.Init.NbrOfConversion = 12;
  hadc3.Init.DiscontinuousConvMode = DISABLE;
  hadc3.Init.ExternalTrigConv = ADC_SOFTWARE_START;
  hadc3.Init.ExternalTrigConvEdge = ADC_EXTERNALTRIGCONVEDGE_NONE;
  hadc3.Init.DMAContinuousRequests = ENABLE;
  hadc3.Init.SamplingMode = ADC_SAMPLING_MODE_NORMAL;
  hadc3.Init.ConversionDataManagement = ADC_CONVERSIONDATA_DMA_CIRCULAR;
  hadc3.Init.Overrun = ADC_OVR_DATA_PRESERVED;
  hadc3.Init.LeftBitShift = ADC_LEFTBITSHIFT_NONE;
  hadc3.Init.OversamplingMode = DISABLE;
  hadc3.Init.Oversampling.Ratio = ADC3_OVERSAMPLING_RATIO_2;
  if (HAL_ADC_Init(&hadc3) != HAL_OK)
  {
    Error_Handler();
  }

  /** Configure Regular Channel
  */
  sConfig.Channel = ADC_CHANNEL_0;
  sConfig.Rank = ADC_REGULAR_RANK_1;
  sConfig.SamplingTime = ADC3_SAMPLETIME_2CYCLES_5;
  sConfig.SingleDiff = ADC_SINGLE_ENDED;
  sConfig.OffsetNumber = ADC_OFFSET_NONE;
  sConfig.Offset = 0;
  sConfig.OffsetSign = ADC3_OFFSET_SIGN_NEGATIVE;
  if (HAL_ADC_ConfigChannel(&hadc3, &sConfig) != HAL_OK)
  {
    Error_Handler();
  }

  /** Configure Regular Channel
  */
  sConfig.Channel = ADC_CHANNEL_1;
  sConfig.Rank = ADC_REGULAR_RANK_2;
  if (HAL_ADC_ConfigChannel(&hadc3, &sConfig) != HAL_OK)
  {
    Error_Handler();
  }

  /** Configure Regular Channel
  */
  sConfig.Channel = ADC_CHANNEL_2;
  sConfig.Rank = ADC_REGULAR_RANK_3;
  if (HAL_ADC_ConfigChannel(&hadc3, &sConfig) != HAL_OK)
  {
    Error_Handler();
  }

  /** Configure Regular Channel
  */
  sConfig.Channel = ADC_CHANNEL_3;
  sConfig.Rank = ADC_REGULAR_RANK_4;
  if (HAL_ADC_ConfigChannel(&hadc3, &sConfig) != HAL_OK)
  {
    Error_Handler();
  }

  /** Configure Regular Channel
  */
  sConfig.Channel = ADC_CHANNEL_4;
  sConfig.Rank = ADC_REGULAR_RANK_5;
  if (HAL_ADC_ConfigChannel(&hadc3, &sConfig) != HAL_OK)
  {
    Error_Handler();
  }

  /** Configure Regular Channel
  */
  sConfig.Channel = ADC_CHANNEL_5;
  sConfig.Rank = ADC_REGULAR_RANK_6;
  if (HAL_ADC_ConfigChannel(&hadc3, &sConfig) != HAL_OK)
  {
    Error_Handler();
  }

  /** Configure Regular Channel
  */
  sConfig.Channel = ADC_CHANNEL_6;
  sConfig.Rank = ADC_REGULAR_RANK_7;
  if (HAL_ADC_ConfigChannel(&hadc3, &sConfig) != HAL_OK)
  {
    Error_Handler();
  }

  /** Configure Regular Channel
  */
  sConfig.Channel = ADC_CHANNEL_7;
  sConfig.Rank = ADC_REGULAR_RANK_8;
  if (HAL_ADC_ConfigChannel(&hadc3, &sConfig) != HAL_OK)
  {
    Error_Handler();
  }

  /** Configure Regular Channel
  */
  sConfig.Channel = ADC_CHANNEL_8;
  sConfig.Rank = ADC_REGULAR_RANK_9;
  if (HAL_ADC_ConfigChannel(&hadc3, &sConfig) != HAL_OK)
  {
    Error_Handler();
  }

  /** Configure Regular Channel
  */
  sConfig.Channel = ADC_CHANNEL_9;
  sConfig.Rank = ADC_REGULAR_RANK_10;
  if (HAL_ADC_ConfigChannel(&hadc3, &sConfig) != HAL_OK)
  {
    Error_Handler();
  }

  /** Configure Regular Channel
  */
  sConfig.Channel = ADC_CHANNEL_10;
  sConfig.Rank = ADC_REGULAR_RANK_11;
  if (HAL_ADC_ConfigChannel(&hadc3, &sConfig) != HAL_OK)
  {
    Error_Handler();
  }

  /** Configure Regular Channel
  */
  sConfig.Channel = ADC_CHANNEL_11;
  sConfig.Rank = ADC_REGULAR_RANK_12;
  if (HAL_ADC_ConfigChannel(&hadc3, &sConfig) != HAL_OK)
  {
    Error_Handler();
  }

}

static void MX_I2C1_Init(void)
{

  hi2c1.Instance = I2C1;
  hi2c1.Init.Timing = 0x20A0C4DF;
  hi2c1.Init.OwnAddress1 = 0;
  hi2c1.Init.AddressingMode = I2C_ADDRESSINGMODE_7BIT;
  hi2c1.Init.DualAddressMode = I2C_DUALADDRESS_DISABLE;
  hi2c1.Init.OwnAddress2 = 0;
  hi2c1.Init.OwnAddress2Masks = I2C_OA2_NOMASK;
  hi2c1.Init.GeneralCallMode = I2C_GENERALCALL_DISABLE;
  hi2c1.Init.NoStretchMode = I2C_NOSTRETCH_DISABLE;
  if (HAL_I2C_Init(&hi2c1) != HAL_OK)
  {
    Error_Handler();
  }

  /** Configure Analogue filter
  */
  if (HAL_I2CEx_ConfigAnalogFilter(&hi2c1, I2C_ANALOGFILTER_ENABLE) != HAL_OK)
  {
    Error_Handler();
  }

  /** Configure Digital filter
  */
  if (HAL_I2CEx_ConfigDigitalFilter(&hi2c1, 0) != HAL_OK)
  {
    Error_Handler();
  }

}

static void MX_I2C2_Init(void)
{

  hi2c2.Instance = I2C2;
  hi2c2.Init.Timing = 0x20A0C4DF;
  hi2c2.Init.OwnAddress1 = 0;
  hi2c2.Init.AddressingMode = I2C_ADDRESSINGMODE_7BIT;
  hi2c2.Init.DualAddressMode = I2C_DUALADDRESS_DISABLE;
  hi2c2.Init.OwnAddress2 = 0;
  hi2c2.Init.OwnAddress2Masks = I2C_OA2_NOMASK;
  hi2c2.Init.GeneralCallMode = I2C_GENERALCALL_DISABLE;
  hi2c2.Init.NoStretchMode = I2C_NOSTRETCH_DISABLE;
  if (HAL_I2C_Init(&hi2c2) != HAL_OK)
  {
    Error_Handler();
  }

  /** Configure Analogue filter
  */
  if (HAL_I2CEx_ConfigAnalogFilter(&hi2c2, I2C_ANALOGFILTER_ENABLE) != HAL_OK)
  {
    Error_Handler();
  }

  /** Configure Digital filter
  */
  if (HAL_I2CEx_ConfigDigitalFilter(&hi2c2, 0) != HAL_OK)
  {
    Error_Handler();
  }

}

static void MX_TIM1_Init(void)
{

  TIM_Encoder_InitTypeDef sConfig = {0};
  TIM_MasterConfigTypeDef sMasterConfig = {0};

  htim1.Instance = TIM1;
  htim1.Init.Prescaler = 0;
  htim1.Init.CounterMode = TIM_COUNTERMODE_UP;
  htim1.Init.Period = 65535;
  htim1.Init.ClockDivision = TIM_CLOCKDIVISION_DIV1;
  htim1.Init.RepetitionCounter = 0;
  htim1.Init.AutoReloadPreload = TIM_AUTORELOAD_PRELOAD_DISABLE;
  sConfig.EncoderMode = TIM_ENCODERMODE_TI12;
  sConfig.IC1Polarity = TIM_ICPOLARITY_RISING;
  sConfig.IC1Selection = TIM_ICSELECTION_DIRECTTI;
  sConfig.IC1Prescaler = TIM_ICPSC_DIV1;
  sConfig.IC1Filter = 0;
  sConfig.IC2Polarity = TIM_ICPOLARITY_RISING;
  sConfig.IC2Selection = TIM_ICSELECTION_DIRECTTI;
  sConfig.IC2Prescaler = TIM_ICPSC_DIV1;
  sConfig.IC2Filter = 0;
  if (HAL_TIM_Encoder_Init(&htim1, &sConfig) != HAL_OK)
  {
    Error_Handler();
  }
  sMasterConfig.MasterOutputTrigger = TIM_TRGO_RESET;
  sMasterConfig.MasterOutputTrigger2 = TIM_TRGO2_RESET;
  sMasterConfig.MasterSlaveMode = TIM_MASTERSLAVEMODE_DISABLE;
  if (HAL_TIMEx_MasterConfigSynchronization(&htim1, &sMasterConfig) != HAL_OK)
  {
    Error_Handler();
  }

}

static void MX_TIM2_Init(void)
{

  TIM_Encoder_InitTypeDef sConfig = {0};
  TIM_MasterConfigTypeDef sMasterConfig = {0};

  htim2.Instance = TIM2;
  htim2.Init.Prescaler = 0;
  htim2.Init.CounterMode = TIM_COUNTERMODE_UP;
  htim2.Init.Period = 4294967295;
  htim2.Init.ClockDivision = TIM_CLOCKDIVISION_DIV1;
  htim2.Init.AutoReloadPreload = TIM_AUTORELOAD_PRELOAD_DISABLE;
  sConfig.EncoderMode = TIM_ENCODERMODE_TI12;
  sConfig.IC1Polarity = TIM_ICPOLARITY_RISING;
  sConfig.IC1Selection = TIM_ICSELECTION_DIRECTTI;
  sConfig.IC1Prescaler = TIM_ICPSC_DIV1;
  sConfig.IC1Filter = 0;
  sConfig.IC2Polarity = TIM_ICPOLARITY_RISING;
  sConfig.IC2Selection = TIM_ICSELECTION_DIRECTTI;
  sConfig.IC2Prescaler = TIM_ICPSC_DIV1;
  sConfig.IC2Filter = 0;
  if (HAL_TIM_Encoder_Init(&htim2, &sConfig) != HAL_OK)
  {
    Error_Handler();
  }
  sMasterConfig.MasterOutputTrigger = TIM_TRGO_RESET;
  sMasterConfig.MasterSlaveMode = TIM_MASTERSLAVEMODE_DISABLE;
  if (HAL_TIMEx_MasterConfigSynchronization(&htim2, &sMasterConfig) != HAL_OK)
  {
    Error_Handler();
  }

}

static void MX_TIM3_Init(void)
{

  TIM_Encoder_InitTypeDef sConfig = {0};
  TIM_MasterConfigTypeDef sMasterConfig = {0};

  htim3.Instance = TIM3;
  htim3.Init.Prescaler = 0;
  htim3.Init.CounterMode = TIM_COUNTERMODE_UP;
  htim3.Init.Period = 65535;
  htim3.Init.ClockDivision = TIM_CLOCKDIVISION_DIV1;
  htim3.Init.AutoReloadPreload = TIM_AUTORELOAD_PRELOAD_DISABLE;
  sConfig.EncoderMode = TIM_ENCODERMODE_TI12;
  sConfig.IC1Polarity = TIM_ICPOLARITY_RISING;
  sConfig.IC1Selection = TIM_ICSELECTION_DIRECTTI;
  sConfig.IC1Prescaler = TIM_ICPSC_DIV1;
  sConfig.IC1Filter = 0;
  sConfig.IC2Polarity = TIM_ICPOLARITY_RISING;
  sConfig.IC2Selection = TIM_ICSELECTION_DIRECTTI;
  sConfig.IC2Prescaler = TIM_ICPSC_DIV1;
  sConfig.IC2Filter = 0;
  if (HAL_TIM_Encoder_Init(&htim3, &sConfig) != HAL_OK)
  {
    Error_Handler();
  }
  sMasterConfig.MasterOutputTrigger = TIM_TRGO_RESET;
  sMasterConfig.MasterSlaveMode = TIM_MASTERSLAVEMODE_DISABLE;
  if (HAL_TIMEx_MasterConfigSynchronization(&htim3, &sMasterConfig) != HAL_OK)
  {
    Error_Handler();
  }

}

static void MX_TIM4_Init(void)
{

  TIM_Encoder_InitTypeDef sConfig = {0};
  TIM_MasterConfigTypeDef sMasterConfig = {0};

  htim4.Instance = TIM4;
  htim4.Init.Prescaler = 0;
  htim4.Init.CounterMode = TIM_COUNTERMODE_UP;
  htim4.Init.Period = 65535;
  htim4.Init.ClockDivision = TIM_CLOCKDIVISION_DIV1;
  htim4.Init.AutoReloadPreload = TIM_AUTORELOAD_PRELOAD_DISABLE;
  sConfig.EncoderMode = TIM_ENCODERMODE_TI12;
  sConfig.IC1Polarity = TIM_ICPOLARITY_RISING;
  sConfig.IC1Selection = TIM_ICSELECTION_DIRECTTI;
  sConfig.IC1Prescaler = TIM_ICPSC_DIV1;
  sConfig.IC1Filter = 0;
  sConfig.IC2Polarity = TIM_ICPOLARITY_RISING;
  sConfig.IC2Selection = TIM_ICSELECTION_DIRECTTI;
  sConfig.IC2Prescaler = TIM_ICPSC_DIV1;
  sConfig.IC2Filter = 0;
  if (HAL_TIM_Encoder_Init(&htim4, &sConfig) != HAL_OK)
  {
    Error_Handler();
  }
  sMasterConfig.MasterOutputTrigger = TIM_TRGO_RESET;
  sMasterConfig.MasterSlaveMode = TIM_MASTERSLAVEMODE_DISABLE;
  if (HAL_TIMEx_MasterConfigSynchronization(&htim4, &sMasterConfig) != HAL_OK)
  {
    Error_Handler();
  }

}

static void MX_TIM5_Init(void)
{

  TIM_MasterConfigTypeDef sMasterConfig = {0};
  TIM_OC_InitTypeDef sConfigOC = {0};

  htim5.Instance = TIM5;
  htim5.Init.Prescaler = 31;
  htim5.Init.CounterMode = TIM_COUNTERMODE_UP;
  htim5.Init.Period = 799;
  htim5.Init.ClockDivision = TIM_CLOCKDIVISION_DIV1;
  htim5.Init.AutoReloadPreload = TIM_AUTORELOAD_PRELOAD_DISABLE;
  if (HAL_TIM_PWM_Init(&htim5) != HAL_OK)
  {
    Error_Handler();
  }
  sMasterConfig.MasterOutputTrigger = TIM_TRGO_RESET;
  sMasterConfig.MasterSlaveMode = TIM_MASTERSLAVEMODE_DISABLE;
  if (HAL_TIMEx_MasterConfigSynchronization(&htim5, &sMasterConfig) != HAL_OK)
  {
    Error_Handler();
  }
  sConfigOC.OCMode = TIM_OCMODE_PWM1;
  sConfigOC.Pulse = 0;
  sConfigOC.OCPolarity = TIM_OCPOLARITY_HIGH;
  sConfigOC.OCFastMode = TIM_OCFAST_DISABLE;
  if (HAL_TIM_PWM_ConfigChannel(&htim5, &sConfigOC, TIM_CHANNEL_1) != HAL_OK)
  {
    Error_Handler();
  }
  if (HAL_TIM_PWM_ConfigChannel(&htim5, &sConfigOC, TIM_CHANNEL_2) != HAL_OK)
  {
    Error_Handler();
  }
  if (HAL_TIM_PWM_ConfigChannel(&htim5, &sConfigOC, TIM_CHANNEL_3) != HAL_OK)
  {
    Error_Handler();
  }
  if (HAL_TIM_PWM_ConfigChannel(&htim5, &sConfigOC, TIM_CHANNEL_4) != HAL_OK)
  {
    Error_Handler();
  }
  HAL_TIM_MspPostInit(&htim5);

}

static void MX_TIM6_Init(void)
{

  TIM_MasterConfigTypeDef sMasterConfig = {0};

  htim6.Instance = TIM6;
  htim6.Init.Prescaler = 255;
  htim6.Init.CounterMode = TIM_COUNTERMODE_UP;
  htim6.Init.Period = 999;
  htim6.Init.AutoReloadPreload = TIM_AUTORELOAD_PRELOAD_DISABLE;
  if (HAL_TIM_Base_Init(&htim6) != HAL_OK)
  {
    Error_Handler();
  }
  sMasterConfig.MasterOutputTrigger = TIM_TRGO_RESET;
  sMasterConfig.MasterSlaveMode = TIM_MASTERSLAVEMODE_DISABLE;
  if (HAL_TIMEx_MasterConfigSynchronization(&htim6, &sMasterConfig) != HAL_OK)
  {
    Error_Handler();
  }

}

static void MX_TIM7_Init(void)
{

  TIM_MasterConfigTypeDef sMasterConfig = {0};

  htim7.Instance = TIM7;
  htim7.Init.Prescaler = 255;
  htim7.Init.CounterMode = TIM_COUNTERMODE_UP;
  htim7.Init.Period = 9999;
  htim7.Init.AutoReloadPreload = TIM_AUTORELOAD_PRELOAD_DISABLE;
  if (HAL_TIM_Base_Init(&htim7) != HAL_OK)
  {
    Error_Handler();
  }
  sMasterConfig.MasterOutputTrigger = TIM_TRGO_RESET;
  sMasterConfig.MasterSlaveMode = TIM_MASTERSLAVEMODE_DISABLE;
  if (HAL_TIMEx_MasterConfigSynchronization(&htim7, &sMasterConfig) != HAL_OK)
  {
    Error_Handler();
  }

}

static void MX_TIM8_Init(void)
{

  TIM_Encoder_InitTypeDef sConfig = {0};
  TIM_MasterConfigTypeDef sMasterConfig = {0};

  htim8.Instance = TIM8;
  htim8.Init.Prescaler = 0;
  htim8.Init.CounterMode = TIM_COUNTERMODE_UP;
  htim8.Init.Period = 65535;
  htim8.Init.ClockDivision = TIM_CLOCKDIVISION_DIV1;
  htim8.Init.RepetitionCounter = 0;
  htim8.Init.AutoReloadPreload = TIM_AUTORELOAD_PRELOAD_DISABLE;
  sConfig.EncoderMode = TIM_ENCODERMODE_TI12;
  sConfig.IC1Polarity = TIM_ICPOLARITY_RISING;
  sConfig.IC1Selection = TIM_ICSELECTION_DIRECTTI;
  sConfig.IC1Prescaler = TIM_ICPSC_DIV1;
  sConfig.IC1Filter = 0;
  sConfig.IC2Polarity = TIM_ICPOLARITY_RISING;
  sConfig.IC2Selection = TIM_ICSELECTION_DIRECTTI;
  sConfig.IC2Prescaler = TIM_ICPSC_DIV1;
  sConfig.IC2Filter = 0;
  if (HAL_TIM_Encoder_Init(&htim8, &sConfig) != HAL_OK)
  {
    Error_Handler();
  }
  sMasterConfig.MasterOutputTrigger = TIM_TRGO_RESET;
  sMasterConfig.MasterOutputTrigger2 = TIM_TRGO2_RESET;
  sMasterConfig.MasterSlaveMode = TIM_MASTERSLAVEMODE_DISABLE;
  if (HAL_TIMEx_MasterConfigSynchronization(&htim8, &sMasterConfig) != HAL_OK)
  {
    Error_Handler();
  }

}

static void MX_TIM12_Init(void)
{

  TIM_MasterConfigTypeDef sMasterConfig = {0};
  TIM_OC_InitTypeDef sConfigOC = {0};

  htim12.Instance = TIM12;
  htim12.Init.Prescaler = 0;
  htim12.Init.CounterMode = TIM_COUNTERMODE_UP;
  htim12.Init.Period = 65535;
  htim12.Init.ClockDivision = TIM_CLOCKDIVISION_DIV1;
  htim12.Init.AutoReloadPreload = TIM_AUTORELOAD_PRELOAD_DISABLE;
  if (HAL_TIM_PWM_Init(&htim12) != HAL_OK)
  {
    Error_Handler();
  }
  sMasterConfig.MasterOutputTrigger = TIM_TRGO_RESET;
  sMasterConfig.MasterSlaveMode = TIM_MASTERSLAVEMODE_DISABLE;
  if (HAL_TIMEx_MasterConfigSynchronization(&htim12, &sMasterConfig) != HAL_OK)
  {
    Error_Handler();
  }
  sConfigOC.OCMode = TIM_OCMODE_PWM1;
  sConfigOC.Pulse = 0;
  sConfigOC.OCPolarity = TIM_OCPOLARITY_HIGH;
  sConfigOC.OCFastMode = TIM_OCFAST_DISABLE;
  if (HAL_TIM_PWM_ConfigChannel(&htim12, &sConfigOC, TIM_CHANNEL_1) != HAL_OK)
  {
    Error_Handler();
  }
  if (HAL_TIM_PWM_ConfigChannel(&htim12, &sConfigOC, TIM_CHANNEL_2) != HAL_OK)
  {
    Error_Handler();
  }
  HAL_TIM_MspPostInit(&htim12);

}

static void MX_TIM13_Init(void)
{

  htim13.Instance = TIM13;
  htim13.Init.Prescaler = 255;
  htim13.Init.CounterMode = TIM_COUNTERMODE_UP;
  htim13.Init.Period = 9999;
  htim13.Init.ClockDivision = TIM_CLOCKDIVISION_DIV1;
  htim13.Init.AutoReloadPreload = TIM_AUTORELOAD_PRELOAD_DISABLE;
  if (HAL_TIM_Base_Init(&htim13) != HAL_OK)
  {
    Error_Handler();
  }

}

static void MX_TIM14_Init(void)
{

  htim14.Instance = TIM14;
  htim14.Init.Prescaler = 255;
  htim14.Init.CounterMode = TIM_COUNTERMODE_UP;
  htim14.Init.Period = 999;
  htim14.Init.ClockDivision = TIM_CLOCKDIVISION_DIV1;
  htim14.Init.AutoReloadPreload = TIM_AUTORELOAD_PRELOAD_DISABLE;
  if (HAL_TIM_Base_Init(&htim14) != HAL_OK)
  {
    Error_Handler();
  }

}

static void MX_TIM15_Init(void)
{

  TIM_MasterConfigTypeDef sMasterConfig = {0};
  TIM_OC_InitTypeDef sConfigOC = {0};
  TIM_BreakDeadTimeConfigTypeDef sBreakDeadTimeConfig = {0};

  htim15.Instance = TIM15;
  htim15.Init.Prescaler = 31;
  htim15.Init.CounterMode = TIM_COUNTERMODE_UP;
  htim15.Init.Period = 799;
  htim15.Init.ClockDivision = TIM_CLOCKDIVISION_DIV1;
  htim15.Init.RepetitionCounter = 0;
  htim15.Init.AutoReloadPreload = TIM_AUTORELOAD_PRELOAD_DISABLE;
  if (HAL_TIM_PWM_Init(&htim15) != HAL_OK)
  {
    Error_Handler();
  }
  sMasterConfig.MasterOutputTrigger = TIM_TRGO_RESET;
  sMasterConfig.MasterSlaveMode = TIM_MASTERSLAVEMODE_DISABLE;
  if (HAL_TIMEx_MasterConfigSynchronization(&htim15, &sMasterConfig) != HAL_OK)
  {
    Error_Handler();
  }
  sConfigOC.OCMode = TIM_OCMODE_PWM1;
  sConfigOC.Pulse = 0;
  sConfigOC.OCPolarity = TIM_OCPOLARITY_HIGH;
  sConfigOC.OCNPolarity = TIM_OCNPOLARITY_HIGH;
  sConfigOC.OCFastMode = TIM_OCFAST_DISABLE;
  sConfigOC.OCIdleState = TIM_OCIDLESTATE_RESET;
  sConfigOC.OCNIdleState = TIM_OCNIDLESTATE_RESET;
  if (HAL_TIM_PWM_ConfigChannel(&htim15, &sConfigOC, TIM_CHANNEL_1) != HAL_OK)
  {
    Error_Handler();
  }
  if (HAL_TIM_PWM_ConfigChannel(&htim15, &sConfigOC, TIM_CHANNEL_2) != HAL_OK)
  {
    Error_Handler();
  }
  sBreakDeadTimeConfig.OffStateRunMode = TIM_OSSR_DISABLE;
  sBreakDeadTimeConfig.OffStateIDLEMode = TIM_OSSI_DISABLE;
  sBreakDeadTimeConfig.LockLevel = TIM_LOCKLEVEL_OFF;
  sBreakDeadTimeConfig.DeadTime = 0;
  sBreakDeadTimeConfig.BreakState = TIM_BREAK_DISABLE;
  sBreakDeadTimeConfig.BreakPolarity = TIM_BREAKPOLARITY_HIGH;
  sBreakDeadTimeConfig.BreakFilter = 0;
  sBreakDeadTimeConfig.AutomaticOutput = TIM_AUTOMATICOUTPUT_DISABLE;
  if (HAL_TIMEx_ConfigBreakDeadTime(&htim15, &sBreakDeadTimeConfig) != HAL_OK)
  {
    Error_Handler();
  }
  HAL_TIM_MspPostInit(&htim15);

}

static void MX_TIM16_Init(void)
{

  TIM_OC_InitTypeDef sConfigOC = {0};
  TIM_BreakDeadTimeConfigTypeDef sBreakDeadTimeConfig = {0};

  htim16.Instance = TIM16;
  htim16.Init.Prescaler = 31;
  htim16.Init.CounterMode = TIM_COUNTERMODE_UP;
  htim16.Init.Period = 799;
  htim16.Init.ClockDivision = TIM_CLOCKDIVISION_DIV1;
  htim16.Init.RepetitionCounter = 0;
  htim16.Init.AutoReloadPreload = TIM_AUTORELOAD_PRELOAD_DISABLE;
  if (HAL_TIM_Base_Init(&htim16) != HAL_OK)
  {
    Error_Handler();
  }
  if (HAL_TIM_PWM_Init(&htim16) != HAL_OK)
  {
    Error_Handler();
  }
  sConfigOC.OCMode = TIM_OCMODE_PWM1;
  sConfigOC.Pulse = 0;
  sConfigOC.OCPolarity = TIM_OCPOLARITY_HIGH;
  sConfigOC.OCNPolarity = TIM_OCNPOLARITY_HIGH;
  sConfigOC.OCFastMode = TIM_OCFAST_DISABLE;
  sConfigOC.OCIdleState = TIM_OCIDLESTATE_RESET;
  sConfigOC.OCNIdleState = TIM_OCNIDLESTATE_RESET;
  if (HAL_TIM_PWM_ConfigChannel(&htim16, &sConfigOC, TIM_CHANNEL_1) != HAL_OK)
  {
    Error_Handler();
  }
  sBreakDeadTimeConfig.OffStateRunMode = TIM_OSSR_DISABLE;
  sBreakDeadTimeConfig.OffStateIDLEMode = TIM_OSSI_DISABLE;
  sBreakDeadTimeConfig.LockLevel = TIM_LOCKLEVEL_OFF;
  sBreakDeadTimeConfig.DeadTime = 0;
  sBreakDeadTimeConfig.BreakState = TIM_BREAK_DISABLE;
  sBreakDeadTimeConfig.BreakPolarity = TIM_BREAKPOLARITY_HIGH;
  sBreakDeadTimeConfig.BreakFilter = 0;
  sBreakDeadTimeConfig.AutomaticOutput = TIM_AUTOMATICOUTPUT_DISABLE;
  if (HAL_TIMEx_ConfigBreakDeadTime(&htim16, &sBreakDeadTimeConfig) != HAL_OK)
  {
    Error_Handler();
  }
  HAL_TIM_MspPostInit(&htim16);

}

static void MX_TIM17_Init(void)
{

  TIM_OC_InitTypeDef sConfigOC = {0};
  TIM_BreakDeadTimeConfigTypeDef sBreakDeadTimeConfig = {0};

  htim17.Instance = TIM17;
  htim17.Init.Prescaler = 31;
  htim17.Init.CounterMode = TIM_COUNTERMODE_UP;
  htim17.Init.Period = 799;
  htim17.Init.ClockDivision = TIM_CLOCKDIVISION_DIV1;
  htim17.Init.RepetitionCounter = 0;
  htim17.Init.AutoReloadPreload = TIM_AUTORELOAD_PRELOAD_DISABLE;
  if (HAL_TIM_Base_Init(&htim17) != HAL_OK)
  {
    Error_Handler();
  }
  if (HAL_TIM_PWM_Init(&htim17) != HAL_OK)
  {
    Error_Handler();
  }
  sConfigOC.OCMode = TIM_OCMODE_PWM1;
  sConfigOC.Pulse = 0;
  sConfigOC.OCPolarity = TIM_OCPOLARITY_HIGH;
  sConfigOC.OCNPolarity = TIM_OCNPOLARITY_HIGH;
  sConfigOC.OCFastMode = TIM_OCFAST_DISABLE;
  sConfigOC.OCIdleState = TIM_OCIDLESTATE_RESET;
  sConfigOC.OCNIdleState = TIM_OCNIDLESTATE_RESET;
  if (HAL_TIM_PWM_ConfigChannel(&htim17, &sConfigOC, TIM_CHANNEL_1) != HAL_OK)
  {
    Error_Handler();
  }
  sBreakDeadTimeConfig.OffStateRunMode = TIM_OSSR_DISABLE;
  sBreakDeadTimeConfig.OffStateIDLEMode = TIM_OSSI_DISABLE;
  sBreakDeadTimeConfig.LockLevel = TIM_LOCKLEVEL_OFF;
  sBreakDeadTimeConfig.DeadTime = 0;
  sBreakDeadTimeConfig.BreakState = TIM_BREAK_DISABLE;
  sBreakDeadTimeConfig.BreakPolarity = TIM_BREAKPOLARITY_HIGH;
  sBreakDeadTimeConfig.BreakFilter = 0;
  sBreakDeadTimeConfig.AutomaticOutput = TIM_AUTOMATICOUTPUT_DISABLE;
  if (HAL_TIMEx_ConfigBreakDeadTime(&htim17, &sBreakDeadTimeConfig) != HAL_OK)
  {
    Error_Handler();
  }
  HAL_TIM_MspPostInit(&htim17);

}

static void MX_TIM23_Init(void)
{

  TIM_Encoder_InitTypeDef sConfig = {0};
  TIM_MasterConfigTypeDef sMasterConfig = {0};

  htim23.Instance = TIM23;
  htim23.Init.Prescaler = 0;
  htim23.Init.CounterMode = TIM_COUNTERMODE_UP;
  htim23.Init.Period = 4294967295;
  htim23.Init.ClockDivision = TIM_CLOCKDIVISION_DIV1;
  htim23.Init.AutoReloadPreload = TIM_AUTORELOAD_PRELOAD_DISABLE;
  sConfig.EncoderMode = TIM_ENCODERMODE_TI12;
  sConfig.IC1Polarity = TIM_ICPOLARITY_RISING;
  sConfig.IC1Selection = TIM_ICSELECTION_DIRECTTI;
  sConfig.IC1Prescaler = TIM_ICPSC_DIV1;
  sConfig.IC1Filter = 0;
  sConfig.IC2Polarity = TIM_ICPOLARITY_RISING;
  sConfig.IC2Selection = TIM_ICSELECTION_DIRECTTI;
  sConfig.IC2Prescaler = TIM_ICPSC_DIV1;
  sConfig.IC2Filter = 0;
  if (HAL_TIM_Encoder_Init(&htim23, &sConfig) != HAL_OK)
  {
    Error_Handler();
  }
  sMasterConfig.MasterOutputTrigger = TIM_TRGO_RESET;
  sMasterConfig.MasterSlaveMode = TIM_MASTERSLAVEMODE_DISABLE;
  if (HAL_TIMEx_MasterConfigSynchronization(&htim23, &sMasterConfig) != HAL_OK)
  {
    Error_Handler();
  }

}

static void MX_TIM24_Init(void)
{

  TIM_Encoder_InitTypeDef sConfig = {0};
  TIM_MasterConfigTypeDef sMasterConfig = {0};

  htim24.Instance = TIM24;
  htim24.Init.Prescaler = 0;
  htim24.Init.CounterMode = TIM_COUNTERMODE_UP;
  htim24.Init.Period = 4294967295;
  htim24.Init.ClockDivision = TIM_CLOCKDIVISION_DIV1;
  htim24.Init.AutoReloadPreload = TIM_AUTORELOAD_PRELOAD_DISABLE;
  sConfig.EncoderMode = TIM_ENCODERMODE_TI12;
  sConfig.IC1Polarity = TIM_ICPOLARITY_RISING;
  sConfig.IC1Selection = TIM_ICSELECTION_DIRECTTI;
  sConfig.IC1Prescaler = TIM_ICPSC_DIV1;
  sConfig.IC1Filter = 0;
  sConfig.IC2Polarity = TIM_ICPOLARITY_RISING;
  sConfig.IC2Selection = TIM_ICSELECTION_DIRECTTI;
  sConfig.IC2Prescaler = TIM_ICPSC_DIV1;
  sConfig.IC2Filter = 0;
  if (HAL_TIM_Encoder_Init(&htim24, &sConfig) != HAL_OK)
  {
    Error_Handler();
  }
  sMasterConfig.MasterOutputTrigger = TIM_TRGO_RESET;
  sMasterConfig.MasterSlaveMode = TIM_MASTERSLAVEMODE_DISABLE;
  if (HAL_TIMEx_MasterConfigSynchronization(&htim24, &sMasterConfig) != HAL_OK)
  {
    Error_Handler();
  }

}

static void MX_USART1_UART_Init(void)
{

  huart1.Instance = USART1;
  huart1.Init.BaudRate = 115200;
  huart1.Init.WordLength = UART_WORDLENGTH_8B;
  huart1.Init.StopBits = UART_STOPBITS_1;
  huart1.Init.Parity = UART_PARITY_NONE;
  huart1.Init.Mode = UART_MODE_TX_RX;
  huart1.Init.HwFlowCtl = UART_HWCONTROL_NONE;
  huart1.Init.OverSampling = UART_OVERSAMPLING_16;
  huart1.Init.OneBitSampling = UART_ONE_BIT_SAMPLE_DISABLE;
  huart1.Init.ClockPrescaler = UART_PRESCALER_DIV1;
  huart1.AdvancedInit.AdvFeatureInit = UART_ADVFEATURE_NO_INIT;
  if (HAL_UART_Init(&huart1) != HAL_OK)
  {
    Error_Handler();
  }
  if (HAL_UARTEx_SetTxFifoThreshold(&huart1, UART_TXFIFO_THRESHOLD_1_8) != HAL_OK)
  {
    Error_Handler();
  }
  if (HAL_UARTEx_SetRxFifoThreshold(&huart1, UART_RXFIFO_THRESHOLD_1_8) != HAL_OK)
  {
    Error_Handler();
  }
  if (HAL_UARTEx_DisableFifoMode(&huart1) != HAL_OK)
  {
    Error_Handler();
  }

}

static void MX_USART2_UART_Init(void)
{

  huart2.Instance = USART2;
  huart2.Init.BaudRate = 115200;
  huart2.Init.WordLength = UART_WORDLENGTH_8B;
  huart2.Init.StopBits = UART_STOPBITS_1;
  huart2.Init.Parity = UART_PARITY_NONE;
  huart2.Init.Mode = UART_MODE_TX_RX;
  huart2.Init.HwFlowCtl = UART_HWCONTROL_NONE;
  huart2.Init.OverSampling = UART_OVERSAMPLING_16;
  huart2.Init.OneBitSampling = UART_ONE_BIT_SAMPLE_DISABLE;
  huart2.Init.ClockPrescaler = UART_PRESCALER_DIV1;
  huart2.AdvancedInit.AdvFeatureInit = UART_ADVFEATURE_NO_INIT;
  if (HAL_UART_Init(&huart2) != HAL_OK)
  {
    Error_Handler();
  }
  if (HAL_UARTEx_SetTxFifoThreshold(&huart2, UART_TXFIFO_THRESHOLD_1_8) != HAL_OK)
  {
    Error_Handler();
  }
  if (HAL_UARTEx_SetRxFifoThreshold(&huart2, UART_RXFIFO_THRESHOLD_1_8) != HAL_OK)
  {
    Error_Handler();
  }
  if (HAL_UARTEx_DisableFifoMode(&huart2) != HAL_OK)
  {
    Error_Handler();
  }

}

static void MX_USART3_UART_Init(void)
{

  huart3.Instance = USART3;
  huart3.Init.BaudRate = 115200;
  huart3.Init.WordLength = UART_WORDLENGTH_8B;
  huart3.Init.StopBits = UART_STOPBITS_1;
  huart3.Init.Parity = UART_PARITY_NONE;
  huart3.Init.Mode = UART_MODE_TX_RX;
  huart3.Init.HwFlowCtl = UART_HWCONTROL_NONE;
  huart3.Init.OverSampling = UART_OVERSAMPLING_16;
  huart3.Init.OneBitSampling = UART_ONE_BIT_SAMPLE_DISABLE;
  huart3.Init.ClockPrescaler = UART_PRESCALER_DIV1;
  huart3.AdvancedInit.AdvFeatureInit = UART_ADVFEATURE_NO_INIT;
  if (HAL_UART_Init(&huart3) != HAL_OK)
  {
    Error_Handler();
  }
  if (HAL_UARTEx_SetTxFifoThreshold(&huart3, UART_TXFIFO_THRESHOLD_1_8) != HAL_OK)
  {
    Error_Handler();
  }
  if (HAL_UARTEx_SetRxFifoThreshold(&huart3, UART_RXFIFO_THRESHOLD_1_8) != HAL_OK)
  {
    Error_Handler();
  }
  if (HAL_UARTEx_DisableFifoMode(&huart3) != HAL_OK)
  {
    Error_Handler();
  }

}

static void MX_DMA_Init(void)
{

  /* DMA controller clock enable */
  __HAL_RCC_DMA1_CLK_ENABLE();
  __HAL_RCC_DMA2_CLK_ENABLE();

  /* DMA interrupt init */
  /* DMA1_Stream0_IRQn interrupt configuration */
  HAL_NVIC_SetPriority(DMA1_Stream0_IRQn, 0, 0);
  HAL_NVIC_EnableIRQ(DMA1_Stream0_IRQn);
  /* DMA1_Stream1_IRQn interrupt configuration */
  HAL_NVIC_SetPriority(DMA1_Stream1_IRQn, 0, 0);
  HAL_NVIC_EnableIRQ(DMA1_Stream1_IRQn);
  /* DMA1_Stream2_IRQn interrupt configuration */
  HAL_NVIC_SetPriority(DMA1_Stream2_IRQn, 0, 0);
  HAL_NVIC_EnableIRQ(DMA1_Stream2_IRQn);
  /* DMA1_Stream3_IRQn interrupt configuration */
  HAL_NVIC_SetPriority(DMA1_Stream3_IRQn, 0, 0);
  HAL_NVIC_EnableIRQ(DMA1_Stream3_IRQn);
  /* DMA1_Stream4_IRQn interrupt configuration */
  HAL_NVIC_SetPriority(DMA1_Stream4_IRQn, 0, 0);
  HAL_NVIC_EnableIRQ(DMA1_Stream4_IRQn);
  /* DMA1_Stream5_IRQn interrupt configuration */
  HAL_NVIC_SetPriority(DMA1_Stream5_IRQn, 0, 0);
  HAL_NVIC_EnableIRQ(DMA1_Stream5_IRQn);
  /* DMA1_Stream6_IRQn interrupt configuration */
  HAL_NVIC_SetPriority(DMA1_Stream6_IRQn, 0, 0);
  HAL_NVIC_EnableIRQ(DMA1_Stream6_IRQn);
  /* DMA1_Stream7_IRQn interrupt configuration */
  HAL_NVIC_SetPriority(DMA1_Stream7_IRQn, 0, 0);
  HAL_NVIC_EnableIRQ(DMA1_Stream7_IRQn);
  /* DMA2_Stream0_IRQn interrupt configuration */
  HAL_NVIC_SetPriority(DMA2_Stream0_IRQn, 0, 0);
  HAL_NVIC_EnableIRQ(DMA2_Stream0_IRQn);

}

static void MX_GPIO_Init(void)
{
  GPIO_InitTypeDef GPIO_InitStruct = {0};

  /* GPIO Ports Clock Enable */
  __HAL_RCC_GPIOE_CLK_ENABLE();
  __HAL_RCC_GPIOC_CLK_ENABLE();
  __HAL_RCC_GPIOF_CLK_ENABLE();
  __HAL_RCC_GPIOH_CLK_ENABLE();
  __HAL_RCC_GPIOA_CLK_ENABLE();
  __HAL_RCC_GPIOB_CLK_ENABLE();
  __HAL_RCC_GPIOG_CLK_ENABLE();
  __HAL_RCC_GPIOD_CLK_ENABLE();

  /*Configure GPIO pin Output Level */
  HAL_GPIO_WritePin(GPIOG, GPIO_PIN_1|GPIO_PIN_2|GPIO_PIN_3|GPIO_PIN_4
                          |GPIO_PIN_5|GPIO_PIN_6|GPIO_PIN_7|GPIO_PIN_8
                          |GPIO_PIN_9|GPIO_PIN_10|GPIO_PIN_11|GPIO_PIN_14
                          |GPIO_PIN_15, GPIO_PIN_RESET);

  /*Configure GPIO pin Output Level */
  HAL_GPIO_WritePin(GPIOB, GPIO_PIN_10, GPIO_PIN_RESET);

  /*Configure GPIO pin Output Level */
  HAL_GPIO_WritePin(GPIOD, GPIO_PIN_10|GPIO_PIN_11|GPIO_PIN_14|GPIO_PIN_15
                          |GPIO_PIN_1|GPIO_PIN_2|GPIO_PIN_3|GPIO_PIN_4, GPIO_PIN_RESET);

  /*Configure GPIO pin Output Level */
  HAL_GPIO_WritePin(GPIOC, GPIO_PIN_8|GPIO_PIN_9, GPIO_PIN_RESET);

  /*Configure GPIO pins : PB1 PB11 PB12 PB13 */
  GPIO_InitStruct.Pin = GPIO_PIN_1|GPIO_PIN_11|GPIO_PIN_12|GPIO_PIN_13;
  GPIO_InitStruct.Mode = GPIO_MODE_IT_RISING;
  GPIO_InitStruct.Pull = GPIO_NOPULL;
  HAL_GPIO_Init(GPIOB, &GPIO_InitStruct);

  /*Configure GPIO pin : PB2 */
  GPIO_InitStruct.Pin = GPIO_PIN_2;
  GPIO_InitStruct.Mode = GPIO_MODE_IT_FALLING;
  GPIO_InitStruct.Pull = GPIO_PULLUP;
  HAL_GPIO_Init(GPIOB, &GPIO_InitStruct);

  /*Configure GPIO pins : PF14 PF15 */
  GPIO_InitStruct.Pin = GPIO_PIN_14|GPIO_PIN_15;
  GPIO_InitStruct.Mode = GPIO_MODE_IT_RISING;
  GPIO_InitStruct.Pull = GPIO_NOPULL;
  HAL_GPIO_Init(GPIOF, &GPIO_InitStruct);

  /*Configure GPIO pin : PG0 */
  GPIO_InitStruct.Pin = GPIO_PIN_0;
  GPIO_InitStruct.Mode = GPIO_MODE_IT_RISING;
  GPIO_InitStruct.Pull = GPIO_NOPULL;
  HAL_GPIO_Init(GPIOG, &GPIO_InitStruct);

  /*Configure GPIO pins : PG1 PG2 PG3 PG4
                           PG5 PG6 PG7 PG8
                           PG9 PG10 PG11 PG14
                           PG15 */
  GPIO_InitStruct.Pin = GPIO_PIN_1|GPIO_PIN_2|GPIO_PIN_3|GPIO_PIN_4
                          |GPIO_PIN_5|GPIO_PIN_6|GPIO_PIN_7|GPIO_PIN_8
                          |GPIO_PIN_9|GPIO_PIN_10|GPIO_PIN_11|GPIO_PIN_14
                          |GPIO_PIN_15;
  GPIO_InitStruct.Mode = GPIO_MODE_OUTPUT_PP;
  GPIO_InitStruct.Pull = GPIO_NOPULL;
  GPIO_InitStruct.Speed = GPIO_SPEED_FREQ_LOW;
  HAL_GPIO_Init(GPIOG, &GPIO_InitStruct);

  /*Configure GPIO pins : PE7 PE10 */
  GPIO_InitStruct.Pin = GPIO_PIN_7|GPIO_PIN_10;
  GPIO_InitStruct.Mode = GPIO_MODE_IT_RISING;
  GPIO_InitStruct.Pull = GPIO_NOPULL;
  HAL_GPIO_Init(GPIOE, &GPIO_InitStruct);

  /*Configure GPIO pin : PB10 */
  GPIO_InitStruct.Pin = GPIO_PIN_10;
  GPIO_InitStruct.Mode = GPIO_MODE_OUTPUT_PP;
  GPIO_InitStruct.Pull = GPIO_NOPULL;
  GPIO_InitStruct.Speed = GPIO_SPEED_FREQ_LOW;
  HAL_GPIO_Init(GPIOB, &GPIO_InitStruct);

  /*Configure GPIO pins : PD10 PD11 PD14 PD15
                           PD1 PD2 PD3 PD4 */
  GPIO_InitStruct.Pin = GPIO_PIN_10|GPIO_PIN_11|GPIO_PIN_14|GPIO_PIN_15
                          |GPIO_PIN_1|GPIO_PIN_2|GPIO_PIN_3|GPIO_PIN_4;
  GPIO_InitStruct.Mode = GPIO_MODE_OUTPUT_PP;
  GPIO_InitStruct.Pull = GPIO_NOPULL;
  GPIO_InitStruct.Speed = GPIO_SPEED_FREQ_LOW;
  HAL_GPIO_Init(GPIOD, &GPIO_InitStruct);

  /*Configure GPIO pins : PC8 PC9 */
  GPIO_InitStruct.Pin = GPIO_PIN_8|GPIO_PIN_9;
  GPIO_InitStruct.Mode = GPIO_MODE_OUTPUT_PP;
  GPIO_InitStruct.Pull = GPIO_NOPULL;
  GPIO_InitStruct.Speed = GPIO_SPEED_FREQ_LOW;
  HAL_GPIO_Init(GPIOC, &GPIO_InitStruct);

  /* EXTI interrupt init*/
  HAL_NVIC_SetPriority(EXTI0_IRQn, 0, 0);
  HAL_NVIC_EnableIRQ(EXTI0_IRQn);

  HAL_NVIC_SetPriority(EXTI1_IRQn, 0, 0);
  HAL_NVIC_EnableIRQ(EXTI1_IRQn);

  HAL_NVIC_SetPriority(EXTI2_IRQn, 0, 0);
  HAL_NVIC_EnableIRQ(EXTI2_IRQn);

  HAL_NVIC_SetPriority(EXTI9_5_IRQn, 0, 0);
  HAL_NVIC_EnableIRQ(EXTI9_5_IRQn);

  HAL_NVIC_SetPriority(EXTI15_10_IRQn, 0, 0);
  HAL_NVIC_EnableIRQ(EXTI15_10_IRQn);

}

void Error_Handler(void)
{
  __disable_irq();
  while (1)
  {
  }
}
